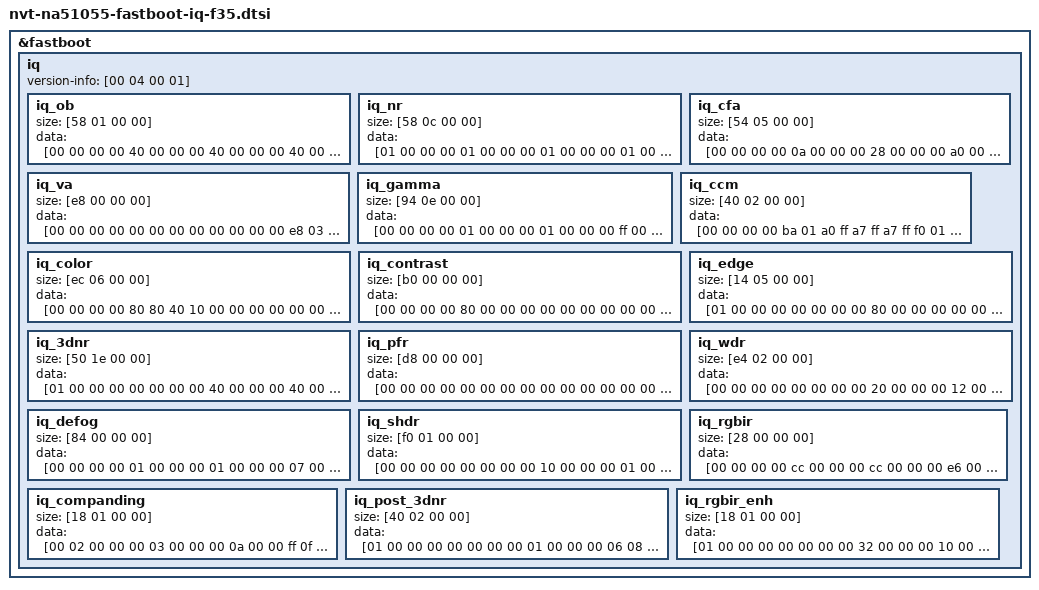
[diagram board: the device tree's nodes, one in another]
/*
 * Novatek Ltd. NA51055 BSP part of dts
 *
 * Cortex-A9
 *
 */

&fastboot {
	     iq {
		version-info = [00 04 00 01];
		iq_ob {
			size = [58 01 00 00];
			data = [00 00 00 00 40 00 00 00 40 00 00 00 40 00 00 00 40 00 00 00 40 00 00 00 40 00 00 00 40 00 00 00 40 00 00 00 40 00 00 00 40 00 00 00 40 00 00 00 40 00 00 00 40 00 00 00 40 00 00 00 40 00 00 00 40 00 00 00 40 00 00 00 40 00 00 00 40 00 00 00 40 00 00 00 40 00 00 00 40 00 00 00 40 00 00 00 40 00 00 00 40 00 00 00 40 00 00 00 40 00 00 00 40 00 00 00 40 00 00 00 40 00 00 00 40 00 00 00 40 00 00 00 40 00 00 00 40 00 00 00 40 00 00 00 40 00 00 00 40 00 00 00 40 00 00 00 40 00 00 00 40 00 00 00 40 00 00 00 40 00 00 00 40 00 00 00 40 00 00 00 40 00 00 00 40 00 00 00 40 00 00 00 40 00 00 00 40 00 00 00 40 00 00 00 40 00 00 00 40 00 00 00 40 00 00 00 40 00 00 00 40 00 00 00 40 00 00 00 40 00 00 00 40 00 00 00 40 00 00 00 40 00 00 00 40 00 00 00 40 00 00 00 40 00 00 00 40 00 00 00 40 00 00 00 40 00 00 00 40 00 00 00 40 00 00 00 40 00 00 00 40 00 00 00 40 00 00 00 40 00 00 00 40 00 00 00 40 00 00 00 40 00 00 00 40 00 00 00 40 00 00 00 40 00 00 00 40 00 00 00 40 00 00 00 40 00 00 00 40 00 00 00 40 00 00 00 40 00 00 00 40 00 00 00];
		};
		iq_nr {
			size = [58 0c 00 00];
			data = [01 00 00 00 01 00 00 00 01 00 00 00 01 00 00 00 01 00 00 00 00 00 00 00 00 00 00 00 00 01 00 00 00 00 00 00 ff 0f 00 00 ff 0f 00 00 ff 0f 00 00 ff 0f 00 00 ff 0f 00 00 ff 0f 00 00 ff 0f 00 00 ff 0f 00 00 ff 0f 00 00 ff 0f 00 00 00 01 80 00 00 00 00 00 00 00 00 00 00 00 00 00 00 00 00 00 00 00 00 00 00 00 00 00 00 00 00 00 00 00 00 00 00 00 00 00 00 00 00 00 00 00 00 00 00 00 00 00 00 00 00 00 00 00 00 00 00 00 00 00 00 00 00 00 00 00 00 00 00 00 00 00 00 00 00 00 00 00 00 00 00 00 00 00 00 00 00 00 00 00 00 00 00 00 00 00 00 00 00 00 80 00 00 00 00 00 00 00 00 00 00 00 00 00 00 00 00 00 00 00 00 00 00 00 00 00 00 00 02 00 00 00 02 00 00 00 00 00 00 00 c6 02 00 00 0c 04 00 00 af 06 00 00 3d 09 00 00 41 0f 00 00 c6 02 00 00 0c 04 00 00 af 06 00 00 3d 09 00 00 41 0f 00 00 00 00 80 00 00 00 00 00 02 00 00 00 03 00 00 00 04 00 00 00 04 00 00 00 06 00 00 00 00 00 00 00 03 00 00 00 05 00 00 00 06 00 00 00 06 00 00 00 06 00 00 00 06 00 00 00 06 00 00 00 06 00 00 00 06 00 00 00 06 00 00 00 06 00 00 00 06 00 00 00 06 00 00 00 06 00 00 00 06 00 00 00 06 00 00 00 00 00 00 00 40 00 00 00 30 00 00 00 08 00 00 00 08 00 00 00 08 00 00 00 08 00 00 00 00 00 00 00 06 00 00 00 00 00 00 00 00 00 00 00 00 00 00 00 c6 02 00 00 0c 04 00 00 af 06 00 00 3d 09 00 00 41 0f 00 00 c6 02 00 00 0c 04 00 00 af 06 00 00 3d 09 00 00 41 0f 00 00 00 00 80 00 00 00 00 00 02 00 00 00 03 00 00 00 04 00 00 00 04 00 00 00 06 00 00 00 00 00 00 00 03 00 00 00 05 00 00 00 06 00 00 00 08 00 00 00 08 00 00 00 08 00 00 00 08 00 00 00 08 00 00 00 08 00 00 00 08 00 00 00 08 00 00 00 08 00 00 00 08 00 00 00 08 00 00 00 08 00 00 00 08 00 00 00 00 00 00 00 20 00 00 00 10 00 00 00 08 00 00 00 08 00 00 00 08 00 00 00 08 00 00 00 00 00 00 00 08 00 00 00 00 00 00 00 00 00 00 00 00 00 00 00 c6 02 00 00 0c 04 00 00 af 06 00 00 3d 09 00 00 41 0f 00 00 c6 02 00 00 0c 04 00 00 af 06 00 00 3d 09 00 00 41 0f 00 00 00 00 80 00 00 00 00 00 02 00 00 00 03 00 00 00 04 00 00 00 04 00 00 00 06 00 00 00 00 00 00 00 06 00 00 00 0a 00 00 00 0c 00 00 00 0e 00 00 00 0c 00 00 00 0a 00 00 00 0a 00 00 00 0a 00 00 00 0a 00 00 00 0a 00 00 00 0a 00 00 00 0a 00 00 00 0a 00 00 00 0a 00 00 00 0a 00 00 00 0a 00 00 00 02 00 00 00 20 00 00 00 00 00 00 00 08 00 00 00 0a 00 00 00 08 00 00 00 0a 00 00 00 00 00 00 00 0c 00 00 00 00 00 00 00 00 00 00 00 00 00 00 00 20 00 00 00 68 04 00 00 45 07 00 00 fe 0b 00 00 ff 0f 00 00 c6 02 00 00 0c 04 00 00 af 06 00 00 3d 09 00 00 41 0f 00 00 00 00 80 00 00 00 00 00 02 00 00 00 03 00 00 00 04 00 00 00 04 00 00 00 06 00 00 00 00 00 00 00 0a 00 00 00 0a 00 00 00 0c 00 00 00 0e 00 00 00 10 00 00 00 11 00 00 00 13 00 00 00 14 00 00 00 14 00 00 00 14 00 00 00 14 00 00 00 14 00 00 00 14 00 00 00 14 00 00 00 14 00 00 00 14 00 00 00 04 00 00 00 00 00 00 00 00 00 00 00 08 00 00 00 0a 00 00 00 08 00 00 00 0a 00 00 00 03 00 00 00 0c 00 00 00 00 00 00 00 01 00 00 00 00 00 00 00 20 00 00 00 56 05 00 00 ce 08 00 00 c4 0c 00 00 ff 0f 00 00 20 00 00 00 cd 05 00 00 92 09 00 00 e1 0d 00 00 ff 0f 00 00 00 00 80 00 00 00 00 00 04 00 00 00 07 00 00 00 08 00 00 00 09 00 00 00 0e 00 00 00 00 00 00 00 0c 00 00 00 12 00 00 00 16 00 00 00 19 00 00 00 1c 00 00 00 1f 00 00 00 21 00 00 00 24 00 00 00 26 00 00 00 28 00 00 00 2a 00 00 00 2c 00 00 00 2e 00 00 00 2f 00 00 00 31 00 00 00 33 00 00 00 04 00 00 00 06 00 00 00 60 00 00 00 08 00 00 00 0a 00 00 00 08 00 00 00 0a 00 00 00 09 00 00 00 10 00 00 00 00 00 00 00 01 00 00 00 00 00 00 00 20 00 00 00 56 05 00 00 ce 08 00 00 c4 0c 00 00 ff 0f 00 00 20 00 00 00 cd 05 00 00 92 09 00 00 e1 0d 00 00 ff 0f 00 00 00 00 80 00 00 00 00 00 04 00 00 00 07 00 00 00 08 00 00 00 09 00 00 00 0e 00 00 00 00 00 00 00 0d 00 00 00 12 00 00 00 16 00 00 00 1a 00 00 00 1d 00 00 00 20 00 00 00 22 00 00 00 25 00 00 00 27 00 00 00 29 00 00 00 2b 00 00 00 2d 00 00 00 2f 00 00 00 31 00 00 00 33 00 00 00 34 00 00 00 04 00 00 00 04 00 00 00 40 00 00 00 08 00 00 00 0a 00 00 00 08 00 00 00 0a 00 00 00 09 00 00 00 10 00 00 00 00 00 00 00 01 00 00 00 00 00 00 00 20 00 00 00 68 04 00 00 45 07 00 00 fe 0b 00 00 ff 0f 00 00 c6 02 00 00 0c 04 00 00 af 06 00 00 3d 09 00 00 41 0f 00 00 00 00 80 00 00 00 00 00 06 00 00 00 09 00 00 00 0b 00 00 00 0c 00 00 00 12 00 00 00 00 00 00 00 08 00 00 00 0c 00 00 00 0f 00 00 00 11 00 00 00 13 00 00 00 15 00 00 00 17 00 00 00 18 00 00 00 1a 00 00 00 1b 00 00 00 1d 00 00 00 1e 00 00 00 1f 00 00 00 20 00 00 00 22 00 00 00 23 00 00 00 06 00 00 00 04 00 00 00 40 00 00 00 08 00 00 00 0a 00 00 00 08 00 00 00 08 00 00 00 0e 00 00 00 0f 00 00 00 00 00 00 00 01 00 00 00 00 00 00 00 c6 02 00 00 0c 04 00 00 af 06 00 00 3d 09 00 00 41 0f 00 00 c6 02 00 00 0c 04 00 00 af 06 00 00 3d 09 00 00 41 0f 00 00 09 00 80 00 00 00 00 00 08 00 00 00 0b 00 00 00 0e 00 00 00 10 00 00 00 17 00 00 00 00 00 00 00 0f 00 00 00 12 00 00 00 1d 00 00 00 21 00 00 00 25 00 00 00 29 00 00 00 2c 00 00 00 2f 00 00 00 32 00 00 00 35 00 00 00 37 00 00 00 3a 00 00 00 3c 00 00 00 3e 00 00 00 41 00 00 00 43 00 00 00 0c 00 00 00 00 00 00 00 00 00 00 00 0a 00 00 00 10 00 00 00 0a 00 00 00 10 00 00 00 06 00 00 00 13 00 00 00 01 00 00 00 02 00 00 00 00 00 00 00 c6 02 00 00 0c 04 00 00 af 06 00 00 3d 09 00 00 41 0f 00 00 c6 02 00 00 0c 04 00 00 af 06 00 00 3d 09 00 00 41 0f 00 00 09 00 80 00 00 00 00 00 0d 00 00 00 12 00 00 00 16 00 00 00 1a 00 00 00 25 00 00 00 00 00 00 00 18 00 00 00 21 00 00 00 29 00 00 00 30 00 00 00 35 00 00 00 3a 00 00 00 3f 00 00 00 43 00 00 00 48 00 00 00 4b 00 00 00 4f 00 00 00 53 00 00 00 56 00 00 00 59 00 00 00 5c 00 00 00 60 00 00 00 00 00 00 00 20 00 00 00 20 00 00 00 10 00 00 00 10 00 00 00 10 00 00 00 10 00 00 00 0a 00 00 00 12 00 00 00 02 00 00 00 03 00 00 00 00 00 00 00 c6 02 00 00 0c 04 00 00 af 06 00 00 3d 09 00 00 41 0f 00 00 c6 02 00 00 0c 04 00 00 af 06 00 00 3d 09 00 00 41 0f 00 00 09 00 80 00 00 00 00 00 16 00 00 00 1f 00 00 00 26 00 00 00 2c 00 00 00 3e 00 00 00 00 00 00 00 1e 00 00 00 2a 00 00 00 34 00 00 00 3c 00 00 00 43 00 00 00 4a 00 00 00 50 00 00 00 55 00 00 00 5b 00 00 00 60 00 00 00 64 00 00 00 69 00 00 00 6d 00 00 00 71 00 00 00 75 00 00 00 79 00 00 00 00 00 00 00 20 00 00 00 40 00 00 00 10 00 00 00 10 00 00 00 10 00 00 00 10 00 00 00 0a 00 00 00 12 00 00 00 02 00 00 00 03 00 00 00 00 00 00 00 c6 02 00 00 0c 04 00 00 af 06 00 00 3d 09 00 00 41 0f 00 00 c6 02 00 00 0c 04 00 00 af 06 00 00 3d 09 00 00 41 0f 00 00 09 00 80 00 00 00 00 00 10 00 00 00 16 00 00 00 1c 00 00 00 20 00 00 00 2d 00 00 00 00 00 00 00 17 00 00 00 20 00 00 00 28 00 00 00 2e 00 00 00 33 00 00 00 38 00 00 00 3d 00 00 00 41 00 00 00 45 00 00 00 49 00 00 00 4c 00 00 00 50 00 00 00 53 00 00 00 56 00 00 00 59 00 00 00 5c 00 00 00 00 00 00 00 20 00 00 00 40 00 00 00 10 00 00 00 10 00 00 00 10 00 00 00 10 00 00 00 18 00 00 00 14 00 00 00 01 00 00 00 01 00 00 00 00 00 00 00 c6 02 00 00 0c 04 00 00 af 06 00 00 3d 09 00 00 41 0f 00 00 c6 02 00 00 0c 04 00 00 af 06 00 00 3d 09 00 00 41 0f 00 00 09 00 80 00 00 00 00 00 21 00 00 00 2f 00 00 00 3a 00 00 00 43 00 00 00 5f 00 00 00 00 00 00 00 27 00 00 00 38 00 00 00 44 00 00 00 4f 00 00 00 58 00 00 00 60 00 00 00 68 00 00 00 70 00 00 00 76 00 00 00 7d 00 00 00 83 00 00 00 89 00 00 00 8e 00 00 00 94 00 00 00 99 00 00 00 9e 00 00 00 00 00 00 00 20 00 00 00 20 00 00 00 10 00 00 00 10 00 00 00 10 00 00 00 10 00 00 00 1a 00 00 00 14 00 00 00 01 00 00 00 01 00 00 00 00 00 00 00 c6 02 00 00 0c 04 00 00 af 06 00 00 3d 09 00 00 41 0f 00 00 c6 02 00 00 0c 04 00 00 af 06 00 00 3d 09 00 00 41 0f 00 00 09 00 80 00 00 00 00 00 2e 00 00 00 42 00 00 00 51 00 00 00 5d 00 00 00 84 00 00 00 00 00 00 00 32 00 00 00 47 00 00 00 57 00 00 00 65 00 00 00 71 00 00 00 7c 00 00 00 86 00 00 00 8f 00 00 00 98 00 00 00 a0 00 00 00 a8 00 00 00 af 00 00 00 b7 00 00 00 be 00 00 00 c4 00 00 00 cb 00 00 00 00 00 00 00 20 00 00 00 20 00 00 00 10 00 00 00 10 00 00 00 10 00 00 00 10 00 00 00 1c 00 00 00 16 00 00 00 01 00 00 00 01 00 00 00 00 00 00 00 c6 02 00 00 0c 04 00 00 af 06 00 00 3d 09 00 00 41 0f 00 00 c6 02 00 00 0c 04 00 00 af 06 00 00 3d 09 00 00 41 0f 00 00 09 00 80 00 00 00 00 00 2e 00 00 00 42 00 00 00 51 00 00 00 5d 00 00 00 84 00 00 00 00 00 00 00 32 00 00 00 47 00 00 00 57 00 00 00 65 00 00 00 71 00 00 00 7c 00 00 00 86 00 00 00 8f 00 00 00 98 00 00 00 a0 00 00 00 a8 00 00 00 af 00 00 00 b7 00 00 00 be 00 00 00 c4 00 00 00 cb 00 00 00 00 00 00 00 20 00 00 00 20 00 00 00 10 00 00 00 10 00 00 00 10 00 00 00 10 00 00 00 1c 00 00 00 16 00 00 00 01 00 00 00 01 00 00 00 00 00 00 00 c6 02 00 00 0c 04 00 00 af 06 00 00 3d 09 00 00 41 0f 00 00 c6 02 00 00 0c 04 00 00 af 06 00 00 3d 09 00 00 41 0f 00 00 09 00 80 00 00 00 00 00 2e 00 00 00 42 00 00 00 51 00 00 00 5d 00 00 00 84 00 00 00 00 00 00 00 32 00 00 00 47 00 00 00 57 00 00 00 65 00 00 00 71 00 00 00 7c 00 00 00 86 00 00 00 8f 00 00 00 98 00 00 00 a0 00 00 00 a8 00 00 00 af 00 00 00 b7 00 00 00 be 00 00 00 c4 00 00 00 cb 00 00 00 00 00 00 00 20 00 00 00 20 00 00 00 10 00 00 00 10 00 00 00 10 00 00 00 10 00 00 00 1c 00 00 00 16 00 00 00 01 00 00 00 01 00 00 00 00 00 00 00 c6 02 00 00 0c 04 00 00 af 06 00 00 3d 09 00 00 41 0f 00 00 c6 02 00 00 0c 04 00 00 af 06 00 00 3d 09 00 00 41 0f 00 00 09 00 80 00 00 00 00 00 2e 00 00 00 42 00 00 00 51 00 00 00 5d 00 00 00 84 00 00 00 00 00 00 00 32 00 00 00 47 00 00 00 57 00 00 00 65 00 00 00 71 00 00 00 7c 00 00 00 86 00 00 00 8f 00 00 00 98 00 00 00 a0 00 00 00 a8 00 00 00 af 00 00 00 b7 00 00 00 be 00 00 00 c4 00 00 00 cb 00 00 00 00 00 00 00 20 00 00 00 20 00 00 00 10 00 00 00 10 00 00 00 10 00 00 00 10 00 00 00 1c 00 00 00 16 00 00 00 01 00 00 00 01 00 00 00];
		};
		iq_cfa {
			size = [54 05 00 00];
			data = [00 00 00 00 0a 00 00 00 28 00 00 00 a0 00 00 00 40 00 00 00 0f 00 00 00 0f 00 00 00 07 00 00 00 04 00 00 00 03 00 00 00 02 00 00 00 02 00 00 00 01 00 00 00 01 00 00 00 01 00 00 00 01 00 00 00 00 00 00 00 00 00 00 00 00 00 00 00 00 00 00 00 00 00 00 00 28 00 00 00 a0 00 00 00 a0 00 00 00 40 00 00 00 0f 00 00 00 0f 00 00 00 07 00 00 00 04 00 00 00 03 00 00 00 02 00 00 00 02 00 00 00 01 00 00 00 01 00 00 00 01 00 00 00 01 00 00 00 00 00 00 00 00 00 00 00 00 00 00 00 00 00 00 00 00 00 00 00 28 00 00 00 28 00 00 00 a0 00 00 00 40 00 00 00 0f 00 00 00 0f 00 00 00 07 00 00 00 04 00 00 00 03 00 00 00 02 00 00 00 02 00 00 00 01 00 00 00 01 00 00 00 01 00 00 00 01 00 00 00 00 00 00 00 00 00 00 00 00 00 00 00 00 00 00 00 00 00 00 00 0a 00 00 00 28 00 00 00 a0 00 00 00 40 00 00 00 0f 00 00 00 0f 00 00 00 07 00 00 00 04 00 00 00 03 00 00 00 02 00 00 00 02 00 00 00 01 00 00 00 01 00 00 00 01 00 00 00 01 00 00 00 00 00 00 00 00 00 00 00 00 00 00 00 00 00 00 00 00 00 00 00 28 00 00 00 28 00 00 00 a0 00 00 00 40 00 00 00 0f 00 00 00 0f 00 00 00 07 00 00 00 04 00 00 00 03 00 00 00 02 00 00 00 02 00 00 00 01 00 00 00 01 00 00 00 01 00 00 00 01 00 00 00 00 00 00 00 00 00 00 00 00 00 00 00 00 00 00 00 00 00 00 00 28 00 00 00 28 00 00 00 a0 00 00 00 40 00 00 00 0f 00 00 00 0f 00 00 00 07 00 00 00 04 00 00 00 03 00 00 00 02 00 00 00 02 00 00 00 01 00 00 00 01 00 00 00 01 00 00 00 01 00 00 00 00 00 00 00 00 00 00 00 00 00 00 00 00 00 00 00 00 00 00 00 0a 00 00 00 28 00 00 00 a0 00 00 00 40 00 00 00 0f 00 00 00 0f 00 00 00 07 00 00 00 04 00 00 00 03 00 00 00 02 00 00 00 02 00 00 00 01 00 00 00 01 00 00 00 01 00 00 00 01 00 00 00 00 00 00 00 00 00 00 00 00 00 00 00 00 00 00 00 00 00 00 00 0a 00 00 00 28 00 00 00 a0 00 00 00 40 00 00 00 0f 00 00 00 0f 00 00 00 07 00 00 00 04 00 00 00 03 00 00 00 02 00 00 00 02 00 00 00 01 00 00 00 01 00 00 00 01 00 00 00 01 00 00 00 00 00 00 00 00 00 00 00 00 00 00 00 00 00 00 00 00 00 00 00 0a 00 00 00 28 00 00 00 a0 00 00 00 40 00 00 00 0f 00 00 00 0f 00 00 00 07 00 00 00 04 00 00 00 03 00 00 00 02 00 00 00 02 00 00 00 01 00 00 00 01 00 00 00 01 00 00 00 01 00 00 00 00 00 00 00 00 00 00 00 00 00 00 00 00 00 00 00 00 00 00 00 0a 00 00 00 28 00 00 00 a0 00 00 00 40 00 00 00 0f 00 00 00 0f 00 00 00 07 00 00 00 04 00 00 00 03 00 00 00 02 00 00 00 02 00 00 00 01 00 00 00 01 00 00 00 01 00 00 00 01 00 00 00 00 00 00 00 00 00 00 00 00 00 00 00 00 00 00 00 00 00 00 00 0a 00 00 00 28 00 00 00 a0 00 00 00 40 00 00 00 0f 00 00 00 0f 00 00 00 07 00 00 00 04 00 00 00 03 00 00 00 02 00 00 00 02 00 00 00 01 00 00 00 01 00 00 00 01 00 00 00 01 00 00 00 00 00 00 00 00 00 00 00 00 00 00 00 00 00 00 00 00 00 00 00 0a 00 00 00 28 00 00 00 a0 00 00 00 20 00 00 00 08 00 00 00 08 00 00 00 03 00 00 00 02 00 00 00 01 00 00 00 01 00 00 00 01 00 00 00 00 00 00 00 00 00 00 00 00 00 00 00 00 00 00 00 00 00 00 00 00 00 00 00 00 00 00 00 00 00 00 00 00 00 00 00 0a 00 00 00 28 00 00 00 a0 00 00 00 20 00 00 00 08 00 00 00 08 00 00 00 03 00 00 00 02 00 00 00 01 00 00 00 01 00 00 00 01 00 00 00 00 00 00 00 00 00 00 00 00 00 00 00 00 00 00 00 00 00 00 00 00 00 00 00 00 00 00 00 00 00 00 00 00 00 00 00 0a 00 00 00 28 00 00 00 a0 00 00 00 40 00 00 00 0f 00 00 00 0f 00 00 00 07 00 00 00 04 00 00 00 03 00 00 00 02 00 00 00 02 00 00 00 01 00 00 00 01 00 00 00 01 00 00 00 01 00 00 00 00 00 00 00 00 00 00 00 00 00 00 00 00 00 00 00 00 00 00 00 0a 00 00 00 28 00 00 00 a0 00 00 00 40 00 00 00 0f 00 00 00 0f 00 00 00 07 00 00 00 04 00 00 00 03 00 00 00 02 00 00 00 02 00 00 00 01 00 00 00 01 00 00 00 01 00 00 00 01 00 00 00 00 00 00 00 00 00 00 00 00 00 00 00 00 00 00 00 00 00 00 00 0a 00 00 00 28 00 00 00 a0 00 00 00 40 00 00 00 0f 00 00 00 0f 00 00 00 07 00 00 00 04 00 00 00 03 00 00 00 02 00 00 00 02 00 00 00 01 00 00 00 01 00 00 00 01 00 00 00 01 00 00 00 00 00 00 00 00 00 00 00 00 00 00 00 00 00 00 00 00 00 00 00 0a 00 00 00 28 00 00 00 a0 00 00 00 40 00 00 00 0f 00 00 00 0f 00 00 00 07 00 00 00 04 00 00 00 03 00 00 00 02 00 00 00 02 00 00 00 01 00 00 00 01 00 00 00 01 00 00 00 01 00 00 00 00 00 00 00 00 00 00 00 00 00 00 00 00 00 00 00 00 00 00 00];
		};
		iq_va {
			size = [e8 00 00 00];
			data = [00 00 00 00 00 00 00 00 00 00 00 00 e8 03 00 00 e8 03 00 00 00 00 00 00 00 00 00 00 e8 03 00 00 e8 03 00 00 00 00 00 00 00 00 00 00 e8 03 00 00 e8 03 00 00 00 00 00 00 00 00 00 00 e8 03 00 00 e8 03 00 00 00 00 00 00 00 00 00 00 e8 03 00 00 e8 03 00 00 02 ff 00 00 03 02 ff 00 00 03 06 00 08 00 06 00 08 00 06 00 08 00 06 00 08 00 06 00 08 00 06 00 08 00 06 00 08 00 06 00 08 00 06 00 08 00 06 00 08 00 06 00 08 00 06 00 08 00 06 00 08 00 06 00 08 00 06 00 08 00 06 00 08 00 06 00 08 00 06 00 08 00 06 00 08 00 06 00 08 00 06 00 08 00 06 00 08 00 06 00 08 00 06 00 08 00 06 00 08 00 06 00 08 00 06 00 08 00 06 00 08 00 06 00 08 00 06 00 08 00 06 00 08 00 06 00 08 00 06 00 08 00 06 00 08 00 00 00];
		};
		iq_gamma {
			size = [94 0e 00 00];
			data = [00 00 00 00 01 00 00 00 01 00 00 00 ff 00 00 00 ff 00 00 00 ff 00 00 00 ff 00 00 00 ff 00 00 00 ff 00 00 00 ff 00 00 00 ff 00 00 00 ff 00 00 00 ff 00 00 00 ff 00 00 00 ff 00 00 00 ff 00 00 00 ff 00 00 00 ff 00 00 00 ff 00 00 00 ff 00 00 00 00 00 00 00 08 00 00 00 10 00 00 00 18 00 00 00 1c 00 00 00 20 00 00 00 24 00 00 00 26 00 00 00 28 00 00 00 29 00 00 00 2a 00 00 00 2b 00 00 00 2c 00 00 00 2d 00 00 00 2e 00 00 00 2f 00 00 00 30 00 00 00 31 00 00 00 32 00 00 00 33 00 00 00 34 00 00 00 35 00 00 00 36 00 00 00 37 00 00 00 38 00 00 00 39 00 00 00 3a 00 00 00 3b 00 00 00 3c 00 00 00 3d 00 00 00 3e 00 00 00 3f 00 00 00 03 00 00 00 03 00 00 00 03 00 00 00 02 00 00 00 02 00 00 00 02 00 00 00 01 00 00 00 01 00 00 00 00 00 00 00 00 00 00 00 00 00 00 00 00 00 00 00 00 00 00 00 00 00 00 00 00 00 00 00 00 00 00 00 00 00 00 00 00 00 00 00 00 00 00 00 00 00 00 00 00 00 00 00 00 00 00 00 00 00 00 00 00 00 00 00 00 00 00 00 00 00 00 00 00 00 00 00 00 00 00 00 00 00 00 00 00 00 00 00 00 00 00 00 00 00 00 00 00 00 00 00 05 00 00 00 18 00 00 00 3f 00 00 00 64 00 00 00 82 00 00 00 a3 00 00 00 cb 00 00 00 ed 00 00 00 fd 00 00 00 0e 01 00 00 1d 01 00 00 2d 01 00 00 3b 01 00 00 49 01 00 00 57 01 00 00 65 01 00 00 71 01 00 00 7e 01 00 00 8a 01 00 00 96 01 00 00 a1 01 00 00 ac 01 00 00 b6 01 00 00 c1 01 00 00 d9 01 00 00 f2 01 00 00 0c 02 00 00 27 02 00 00 40 02 00 00 5a 02 00 00 73 02 00 00 8d 02 00 00 ad 02 00 00 cd 02 00 00 ed 02 00 00 0e 03 00 00 4e 03 00 00 8f 03 00 00 d0 03 00 00 11 04 00 00 92 04 00 00 14 05 00 00 95 05 00 00 17 06 00 00 94 06 00 00 0f 07 00 00 89 07 00 00 02 08 00 00 80 08 00 00 ff 08 00 00 80 09 00 00 02 0a 00 00 85 0a 00 00 09 0b 00 00 8f 0b 00 00 17 0c 00 00 99 0c 00 00 1b 0d 00 00 9d 0d 00 00 20 0e 00 00 9b 0e 00 00 15 0f 00 00 8b 0f 00 00 ff 0f 00 00 00 00 00 00 08 00 00 00 10 00 00 00 18 00 00 00 1c 00 00 00 20 00 00 00 24 00 00 00 26 00 00 00 28 00 00 00 29 00 00 00 2a 00 00 00 2b 00 00 00 2c 00 00 00 2d 00 00 00 2e 00 00 00 2f 00 00 00 30 00 00 00 31 00 00 00 32 00 00 00 33 00 00 00 34 00 00 00 35 00 00 00 36 00 00 00 37 00 00 00 38 00 00 00 39 00 00 00 3a 00 00 00 3b 00 00 00 3c 00 00 00 3d 00 00 00 3e 00 00 00 3f 00 00 00 03 00 00 00 03 00 00 00 03 00 00 00 02 00 00 00 02 00 00 00 02 00 00 00 01 00 00 00 01 00 00 00 00 00 00 00 00 00 00 00 00 00 00 00 00 00 00 00 00 00 00 00 00 00 00 00 00 00 00 00 00 00 00 00 00 00 00 00 00 00 00 00 00 00 00 00 00 00 00 00 00 00 00 00 00 00 00 00 00 00 00 00 00 00 00 00 00 00 00 00 00 00 00 00 00 00 00 00 00 00 00 00 00 00 00 00 00 00 00 00 00 00 00 00 00 00 00 00 05 00 00 00 00 00 00 00 00 00 00 00 10 00 00 00 20 00 00 00 30 00 00 00 40 00 00 00 50 00 00 00 60 00 00 00 70 00 00 00 80 00 00 00 90 00 00 00 a0 00 00 00 b0 00 00 00 c0 00 00 00 d0 00 00 00 e0 00 00 00 f0 00 00 00 00 01 00 00 10 01 00 00 20 01 00 00 30 01 00 00 40 01 00 00 50 01 00 00 60 01 00 00 70 01 00 00 80 01 00 00 a0 01 00 00 c0 01 00 00 e0 01 00 00 00 02 00 00 20 02 00 00 40 02 00 00 60 02 00 00 80 02 00 00 a0 02 00 00 c0 02 00 00 e0 02 00 00 00 03 00 00 40 03 00 00 80 03 00 00 c0 03 00 00 00 04 00 00 80 04 00 00 00 05 00 00 80 05 00 00 00 06 00 00 80 06 00 00 00 07 00 00 80 07 00 00 00 08 00 00 80 08 00 00 00 09 00 00 80 09 00 00 00 0a 00 00 80 0a 00 00 00 0b 00 00 80 0b 00 00 00 0c 00 00 80 0c 00 00 00 0d 00 00 80 0d 00 00 00 0e 00 00 80 0e 00 00 00 0f 00 00 80 0f 00 00 ff 0f 00 00 19 00 00 00 00 00 00 00 10 00 00 00 20 00 00 00 30 00 00 00 40 00 00 00 50 00 00 00 60 00 00 00 70 00 00 00 80 00 00 00 90 00 00 00 a0 00 00 00 b0 00 00 00 c0 00 00 00 d0 00 00 00 e0 00 00 00 f0 00 00 00 00 01 00 00 10 01 00 00 20 01 00 00 30 01 00 00 40 01 00 00 50 01 00 00 60 01 00 00 70 01 00 00 80 01 00 00 a0 01 00 00 c0 01 00 00 e0 01 00 00 00 02 00 00 20 02 00 00 40 02 00 00 60 02 00 00 80 02 00 00 a0 02 00 00 c0 02 00 00 e0 02 00 00 00 03 00 00 40 03 00 00 80 03 00 00 c0 03 00 00 00 04 00 00 80 04 00 00 00 05 00 00 80 05 00 00 00 06 00 00 80 06 00 00 00 07 00 00 80 07 00 00 00 08 00 00 80 08 00 00 00 09 00 00 80 09 00 00 00 0a 00 00 80 0a 00 00 00 0b 00 00 80 0b 00 00 00 0c 00 00 80 0c 00 00 00 0d 00 00 80 0d 00 00 00 0e 00 00 80 0e 00 00 00 0f 00 00 80 0f 00 00 ff 0f 00 00 32 00 00 00 00 00 00 00 10 00 00 00 20 00 00 00 30 00 00 00 40 00 00 00 50 00 00 00 60 00 00 00 70 00 00 00 80 00 00 00 90 00 00 00 a0 00 00 00 b0 00 00 00 c0 00 00 00 d0 00 00 00 e0 00 00 00 f0 00 00 00 00 01 00 00 10 01 00 00 20 01 00 00 30 01 00 00 40 01 00 00 50 01 00 00 60 01 00 00 70 01 00 00 80 01 00 00 a0 01 00 00 c0 01 00 00 e0 01 00 00 00 02 00 00 20 02 00 00 40 02 00 00 60 02 00 00 80 02 00 00 a0 02 00 00 c0 02 00 00 e0 02 00 00 00 03 00 00 40 03 00 00 80 03 00 00 c0 03 00 00 00 04 00 00 80 04 00 00 00 05 00 00 80 05 00 00 00 06 00 00 80 06 00 00 00 07 00 00 80 07 00 00 00 08 00 00 80 08 00 00 00 09 00 00 80 09 00 00 00 0a 00 00 80 0a 00 00 00 0b 00 00 80 0b 00 00 00 0c 00 00 80 0c 00 00 00 0d 00 00 80 0d 00 00 00 0e 00 00 80 0e 00 00 00 0f 00 00 80 0f 00 00 ff 0f 00 00 4b 00 00 00 00 00 00 00 10 00 00 00 20 00 00 00 30 00 00 00 40 00 00 00 50 00 00 00 60 00 00 00 70 00 00 00 80 00 00 00 90 00 00 00 a0 00 00 00 b0 00 00 00 c0 00 00 00 d0 00 00 00 e0 00 00 00 f0 00 00 00 00 01 00 00 10 01 00 00 20 01 00 00 30 01 00 00 40 01 00 00 50 01 00 00 60 01 00 00 70 01 00 00 80 01 00 00 a0 01 00 00 c0 01 00 00 e0 01 00 00 00 02 00 00 20 02 00 00 40 02 00 00 60 02 00 00 80 02 00 00 a0 02 00 00 c0 02 00 00 e0 02 00 00 00 03 00 00 40 03 00 00 80 03 00 00 c0 03 00 00 00 04 00 00 80 04 00 00 00 05 00 00 80 05 00 00 00 06 00 00 80 06 00 00 00 07 00 00 80 07 00 00 00 08 00 00 80 08 00 00 00 09 00 00 80 09 00 00 00 0a 00 00 80 0a 00 00 00 0b 00 00 80 0b 00 00 00 0c 00 00 80 0c 00 00 00 0d 00 00 80 0d 00 00 00 0e 00 00 80 0e 00 00 00 0f 00 00 80 0f 00 00 ff 0f 00 00 64 00 00 00 00 00 00 00 10 00 00 00 20 00 00 00 30 00 00 00 40 00 00 00 50 00 00 00 60 00 00 00 70 00 00 00 80 00 00 00 90 00 00 00 a0 00 00 00 b0 00 00 00 c0 00 00 00 d0 00 00 00 e0 00 00 00 f0 00 00 00 00 01 00 00 10 01 00 00 20 01 00 00 30 01 00 00 40 01 00 00 50 01 00 00 60 01 00 00 70 01 00 00 80 01 00 00 a0 01 00 00 c0 01 00 00 e0 01 00 00 00 02 00 00 20 02 00 00 40 02 00 00 60 02 00 00 80 02 00 00 a0 02 00 00 c0 02 00 00 e0 02 00 00 00 03 00 00 40 03 00 00 80 03 00 00 c0 03 00 00 00 04 00 00 80 04 00 00 00 05 00 00 80 05 00 00 00 06 00 00 80 06 00 00 00 07 00 00 80 07 00 00 00 08 00 00 80 08 00 00 00 09 00 00 80 09 00 00 00 0a 00 00 80 0a 00 00 00 0b 00 00 80 0b 00 00 00 0c 00 00 80 0c 00 00 00 0d 00 00 80 0d 00 00 00 0e 00 00 80 0e 00 00 00 0f 00 00 80 0f 00 00 ff 0f 00 00 00 00 00 00 32 00 00 00 5a 00 00 00 78 00 00 00 97 00 00 00 b4 00 00 00 cc 00 00 00 e5 00 00 00 fc 00 00 00 14 01 00 00 2c 01 00 00 42 01 00 00 56 01 00 00 67 01 00 00 76 01 00 00 83 01 00 00 8e 01 00 00 9a 01 00 00 a6 01 00 00 b1 01 00 00 bc 01 00 00 c6 01 00 00 cf 01 00 00 d8 01 00 00 e1 01 00 00 ea 01 00 00 f2 01 00 00 fb 01 00 00 03 02 00 00 0b 02 00 00 12 02 00 00 1a 02 00 00 21 02 00 00 28 02 00 00 2f 02 00 00 36 02 00 00 3d 02 00 00 43 02 00 00 4a 02 00 00 50 02 00 00 57 02 00 00 5d 02 00 00 63 02 00 00 69 02 00 00 6e 02 00 00 74 02 00 00 79 02 00 00 7f 02 00 00 84 02 00 00 8a 02 00 00 90 02 00 00 96 02 00 00 9b 02 00 00 a1 02 00 00 a7 02 00 00 ac 02 00 00 b2 02 00 00 b7 02 00 00 bd 02 00 00 c2 02 00 00 c8 02 00 00 cd 02 00 00 d2 02 00 00 d7 02 00 00 dd 02 00 00 e2 02 00 00 e7 02 00 00 ec 02 00 00 f2 02 00 00 f7 02 00 00 fc 02 00 00 01 03 00 00 06 03 00 00 0b 03 00 00 11 03 00 00 16 03 00 00 1b 03 00 00 20 03 00 00 25 03 00 00 2a 03 00 00 2f 03 00 00 34 03 00 00 38 03 00 00 3d 03 00 00 42 03 00 00 47 03 00 00 4c 03 00 00 51 03 00 00 55 03 00 00 5a 03 00 00 5f 03 00 00 63 03 00 00 68 03 00 00 6d 03 00 00 71 03 00 00 76 03 00 00 7b 03 00 00 7f 03 00 00 84 03 00 00 88 03 00 00 8c 03 00 00 91 03 00 00 95 03 00 00 99 03 00 00 9e 03 00 00 a2 03 00 00 a6 03 00 00 ab 03 00 00 af 03 00 00 b3 03 00 00 b7 03 00 00 bb 03 00 00 bf 03 00 00 c4 03 00 00 c8 03 00 00 cc 03 00 00 d0 03 00 00 d4 03 00 00 d8 03 00 00 dc 03 00 00 e0 03 00 00 e4 03 00 00 e8 03 00 00 eb 03 00 00 ef 03 00 00 f3 03 00 00 f7 03 00 00 fb 03 00 00 ff 03 00 00 06 00 00 00 00 00 00 00 32 00 00 00 5a 00 00 00 78 00 00 00 97 00 00 00 b4 00 00 00 cc 00 00 00 e5 00 00 00 fc 00 00 00 14 01 00 00 2c 01 00 00 42 01 00 00 56 01 00 00 67 01 00 00 76 01 00 00 83 01 00 00 8e 01 00 00 9a 01 00 00 a6 01 00 00 b1 01 00 00 bc 01 00 00 c6 01 00 00 cf 01 00 00 d8 01 00 00 e1 01 00 00 ea 01 00 00 f2 01 00 00 fb 01 00 00 03 02 00 00 0b 02 00 00 12 02 00 00 1a 02 00 00 21 02 00 00 28 02 00 00 2f 02 00 00 36 02 00 00 3d 02 00 00 43 02 00 00 4a 02 00 00 50 02 00 00 57 02 00 00 5d 02 00 00 63 02 00 00 69 02 00 00 6e 02 00 00 74 02 00 00 79 02 00 00 7f 02 00 00 84 02 00 00 8a 02 00 00 90 02 00 00 96 02 00 00 9b 02 00 00 a1 02 00 00 a7 02 00 00 ac 02 00 00 b2 02 00 00 b7 02 00 00 bd 02 00 00 c2 02 00 00 c8 02 00 00 cd 02 00 00 d2 02 00 00 d7 02 00 00 dd 02 00 00 e2 02 00 00 e7 02 00 00 ec 02 00 00 f2 02 00 00 f7 02 00 00 fc 02 00 00 01 03 00 00 06 03 00 00 0b 03 00 00 11 03 00 00 16 03 00 00 1b 03 00 00 20 03 00 00 25 03 00 00 2a 03 00 00 2f 03 00 00 34 03 00 00 38 03 00 00 3d 03 00 00 42 03 00 00 47 03 00 00 4c 03 00 00 51 03 00 00 55 03 00 00 5a 03 00 00 5f 03 00 00 63 03 00 00 68 03 00 00 6d 03 00 00 71 03 00 00 76 03 00 00 7b 03 00 00 7f 03 00 00 84 03 00 00 88 03 00 00 8c 03 00 00 91 03 00 00 95 03 00 00 99 03 00 00 9e 03 00 00 a2 03 00 00 a6 03 00 00 ab 03 00 00 af 03 00 00 b3 03 00 00 b7 03 00 00 bb 03 00 00 bf 03 00 00 c4 03 00 00 c8 03 00 00 cc 03 00 00 d0 03 00 00 d4 03 00 00 d8 03 00 00 dc 03 00 00 e0 03 00 00 e4 03 00 00 e8 03 00 00 eb 03 00 00 ef 03 00 00 f3 03 00 00 f7 03 00 00 fb 03 00 00 ff 03 00 00 04 00 00 00 00 00 00 00 32 00 00 00 5a 00 00 00 78 00 00 00 97 00 00 00 b4 00 00 00 cc 00 00 00 e5 00 00 00 fc 00 00 00 14 01 00 00 2c 01 00 00 42 01 00 00 56 01 00 00 67 01 00 00 76 01 00 00 83 01 00 00 8e 01 00 00 9a 01 00 00 a6 01 00 00 b1 01 00 00 bc 01 00 00 c6 01 00 00 cf 01 00 00 d8 01 00 00 e1 01 00 00 ea 01 00 00 f2 01 00 00 fb 01 00 00 03 02 00 00 0b 02 00 00 12 02 00 00 1a 02 00 00 21 02 00 00 28 02 00 00 2f 02 00 00 36 02 00 00 3d 02 00 00 43 02 00 00 4a 02 00 00 50 02 00 00 57 02 00 00 5d 02 00 00 63 02 00 00 69 02 00 00 6e 02 00 00 74 02 00 00 79 02 00 00 7f 02 00 00 84 02 00 00 8a 02 00 00 90 02 00 00 96 02 00 00 9b 02 00 00 a1 02 00 00 a7 02 00 00 ac 02 00 00 b2 02 00 00 b7 02 00 00 bd 02 00 00 c2 02 00 00 c8 02 00 00 cd 02 00 00 d2 02 00 00 d7 02 00 00 dd 02 00 00 e2 02 00 00 e7 02 00 00 ec 02 00 00 f2 02 00 00 f7 02 00 00 fc 02 00 00 01 03 00 00 06 03 00 00 0b 03 00 00 11 03 00 00 16 03 00 00 1b 03 00 00 20 03 00 00 25 03 00 00 2a 03 00 00 2f 03 00 00 34 03 00 00 38 03 00 00 3d 03 00 00 42 03 00 00 47 03 00 00 4c 03 00 00 51 03 00 00 55 03 00 00 5a 03 00 00 5f 03 00 00 63 03 00 00 68 03 00 00 6d 03 00 00 71 03 00 00 76 03 00 00 7b 03 00 00 7f 03 00 00 84 03 00 00 88 03 00 00 8c 03 00 00 91 03 00 00 95 03 00 00 99 03 00 00 9e 03 00 00 a2 03 00 00 a6 03 00 00 ab 03 00 00 af 03 00 00 b3 03 00 00 b7 03 00 00 bb 03 00 00 bf 03 00 00 c4 03 00 00 c8 03 00 00 cc 03 00 00 d0 03 00 00 d4 03 00 00 d8 03 00 00 dc 03 00 00 e0 03 00 00 e4 03 00 00 e8 03 00 00 eb 03 00 00 ef 03 00 00 f3 03 00 00 f7 03 00 00 fb 03 00 00 ff 03 00 00];
		};
		iq_ccm {
			size = [40 02 00 00];
			data = [00 00 00 00 ba 01 a0 ff a7 ff a7 ff f0 01 6a ff 0c 00 38 ff bb 01 80 80 80 80 80 80 80 80 80 80 80 80 80 80 80 80 80 80 80 80 80 80 80 80 00 00 00 00 00 00 00 00 00 00 00 00 00 00 00 00 00 00 00 00 00 00 00 00 00 00 00 00 00 00 00 00 00 00 00 00 00 00 00 00 00 00 00 00 00 00 00 00 00 00 00 00 00 00 00 00 00 00 00 00 00 00 00 00 00 00 00 00 00 00 00 00 00 00 00 00 00 00 00 00 00 00 00 00 00 00 00 00 00 00 00 00 00 00 00 00 00 00 64 19 00 00 70 02 28 ff 68 ff 58 ff 8f 02 19 ff eb ff db fe 3a 02 80 80 80 80 80 80 80 80 80 80 80 80 80 80 80 80 80 80 80 80 80 80 80 80 00 00 0a 00 00 00 0a 00 00 00 00 00 00 00 00 00 00 00 00 00 00 00 00 00 00 00 00 00 00 00 00 00 00 00 00 00 00 00 00 00 00 00 00 00 00 00 00 00 00 00 00 00 00 00 00 00 00 00 00 00 00 00 00 00 00 00 00 00 00 00 00 00 00 00 00 00 00 00 00 00 00 00 00 00 00 00 00 00 00 00 00 00 00 00 00 00 00 00 ac 0d 00 00 db 01 73 ff b2 ff 39 ff 12 02 b5 ff cd ff 88 fe ab 02 80 80 80 80 80 80 80 80 80 80 80 80 80 80 80 80 80 80 80 80 80 80 80 80 00 00 00 00 00 00 00 00 00 00 00 00 00 00 00 00 00 00 00 00 00 00 00 00 00 00 00 00 00 00 00 00 00 00 00 00 00 00 00 00 00 00 00 00 00 00 00 00 00 00 00 00 00 00 00 00 00 00 00 00 00 00 00 00 00 00 00 00 00 00 00 00 00 00 00 00 00 00 00 00 00 00 00 00 00 00 00 00 00 00 00 00 00 00 00 00 00 00 f0 0a 00 00 31 01 0e 00 c0 ff 1c ff 04 02 e1 ff 76 ff e3 fd a7 03 80 80 80 80 80 80 80 80 80 80 80 80 80 80 80 80 80 80 80 80 80 80 80 80 00 00 00 00 00 00 00 00 00 00 00 00 00 00 00 00 00 00 00 00 00 00 00 00 00 00 00 00 00 00 00 00 00 00 00 00 00 00 00 00 00 00 00 00 00 00 00 00 00 00 00 00 00 00 00 00 00 00 00 00 00 00 00 00 00 00 00 00 00 00 00 00 00 00 00 00 00 00 00 00 00 00 00 00 00 00 00 00 00 00 00 00 00 00 00 00 00 00];
		};
		iq_color {
			size = [ec 06 00 00];
			data = [00 00 00 00 80 80 40 10 00 00 00 00 00 00 00 00 00 00 00 00 00 14 0f 0a 05 00 00 00 00 00 00 00 00 00 05 0a 0f 00 00 00 80 00 00 00 80 00 00 00 80 00 00 00 80 00 00 00 80 00 00 00 80 00 00 00 80 00 00 00 80 00 00 00 80 00 00 00 80 00 00 00 80 00 00 00 80 00 00 00 80 00 00 00 80 00 00 00 80 00 00 00 80 00 00 00 80 00 00 00 b4 80 40 10 00 00 00 00 00 00 00 00 00 00 00 00 00 14 0f 0a 05 00 00 00 00 00 00 00 00 00 05 0a 0f 00 00 00 80 00 00 00 80 00 00 00 80 00 00 00 80 00 00 00 80 00 00 00 80 00 00 00 80 00 00 00 80 00 00 00 80 00 00 00 80 00 00 00 80 00 00 00 80 00 00 00 80 00 00 00 80 00 00 00 80 00 00 00 80 00 00 00 80 00 00 00 96 80 40 10 00 00 00 00 00 00 00 00 00 00 00 00 00 14 0f 0a 05 00 00 00 00 00 00 00 00 00 05 0a 0f 00 00 00 80 00 00 00 80 00 00 00 80 00 00 00 80 00 00 00 80 00 00 00 80 00 00 00 80 00 00 00 80 00 00 00 80 00 00 00 80 00 00 00 80 00 00 00 80 00 00 00 80 00 00 00 80 00 00 00 80 00 00 00 80 00 00 00 80 00 00 00 96 80 40 10 00 00 00 00 00 00 00 00 00 00 00 00 00 14 0f 0a 05 00 00 00 00 00 00 00 00 00 05 0a 0f 00 00 00 80 00 00 00 80 00 00 00 80 00 00 00 80 00 00 00 80 00 00 00 80 00 00 00 80 00 00 00 80 00 00 00 80 00 00 00 80 00 00 00 80 00 00 00 80 00 00 00 80 00 00 00 80 00 00 00 80 00 00 00 80 00 00 00 80 00 00 00 8c 80 40 10 00 00 00 00 00 00 00 00 00 00 00 00 00 00 00 00 00 00 00 00 00 00 00 00 00 00 05 0a 0f 00 00 00 80 00 00 00 80 00 00 00 80 00 00 00 80 00 00 00 80 00 00 00 80 00 00 00 80 00 00 00 80 00 00 00 80 00 00 00 80 00 00 00 80 00 00 00 80 00 00 00 80 00 00 00 80 00 00 00 80 00 00 00 80 00 00 00 80 00 00 00 6e c4 86 5a 2c 0c 00 00 00 00 00 00 00 00 00 00 00 14 0f 0a 05 00 00 00 00 00 00 00 00 00 05 0a 0f 00 00 00 80 00 00 00 80 00 00 00 80 00 00 00 80 00 00 00 80 00 00 00 80 00 00 00 80 00 00 00 80 00 00 00 80 00 00 00 80 00 00 00 80 00 00 00 80 00 00 00 80 00 00 00 80 00 00 00 80 00 00 00 80 00 00 00 80 00 00 00 78 e7 bb 8d 58 27 0c 00 00 00 00 00 00 00 00 00 00 1e 0f 0a 05 00 00 00 00 00 00 00 00 00 05 0a 0f 00 00 00 80 00 00 00 80 00 00 00 80 00 00 00 80 00 00 00 80 00 00 00 80 00 00 00 80 00 00 00 80 00 00 00 80 00 00 00 80 00 00 00 80 00 00 00 80 00 00 00 80 00 00 00 80 00 00 00 80 00 00 00 80 00 00 00 80 00 00 00 64 e7 bb 8d 58 27 0c 00 00 00 00 00 00 00 00 00 00 1e 0f 0a 05 00 00 00 00 00 00 00 00 00 05 0a 0f 00 00 00 80 00 00 00 80 00 00 00 80 00 00 00 80 00 00 00 80 00 00 00 80 00 00 00 80 00 00 00 80 00 00 00 80 00 00 00 80 00 00 00 80 00 00 00 80 00 00 00 80 00 00 00 80 00 00 00 80 00 00 00 80 00 00 00 80 00 00 00 76 80 43 10 00 00 00 00 00 00 00 00 00 00 00 00 00 14 0f 0a 05 00 00 00 00 00 00 00 00 00 05 0a 0f 00 00 00 80 00 00 00 80 00 00 00 80 00 00 00 80 00 00 00 80 00 00 00 80 00 00 00 80 00 00 00 80 00 00 00 80 00 00 00 80 00 00 00 80 00 00 00 80 00 00 00 80 00 00 00 80 00 00 00 80 00 00 00 80 00 00 00 80 00 00 00 80 80 40 10 00 00 00 00 00 00 00 00 00 00 00 00 00 14 0f 0a 05 00 00 00 00 00 00 00 00 00 05 0a 0f 00 00 00 80 00 00 00 80 00 00 00 80 00 00 00 80 00 00 00 80 00 00 00 80 00 00 00 80 00 00 00 80 00 00 00 80 00 00 00 80 00 00 00 80 00 00 00 80 00 00 00 80 00 00 00 80 00 00 00 80 00 00 00 80 00 00 00 80 00 00 00 80 80 40 10 00 00 00 00 00 00 00 00 00 00 00 00 00 14 0f 0a 05 00 00 00 00 00 00 00 00 00 05 0a 0f 00 00 00 80 00 00 00 80 00 00 00 80 00 00 00 80 00 00 00 80 00 00 00 80 00 00 00 80 00 00 00 80 00 00 00 80 00 00 00 80 00 00 00 80 00 00 00 80 00 00 00 80 00 00 00 80 00 00 00 80 00 00 00 80 00 00 00 80 00 00 00 80 80 40 10 00 00 00 00 00 00 00 00 00 00 00 00 00 14 0f 0a 05 00 00 00 00 00 00 00 00 00 05 0a 0f 00 00 00 80 00 00 00 80 00 00 00 80 00 00 00 80 00 00 00 80 00 00 00 80 00 00 00 80 00 00 00 80 00 00 00 80 00 00 00 80 00 00 00 80 00 00 00 80 00 00 00 80 00 00 00 80 00 00 00 80 00 00 00 80 00 00 00 80 00 00 00 80 80 40 10 00 00 00 00 00 00 00 00 00 00 00 00 00 14 0f 0a 05 00 00 00 00 00 00 00 00 00 05 0a 0f 00 00 00 80 00 00 00 80 00 00 00 80 00 00 00 80 00 00 00 80 00 00 00 80 00 00 00 80 00 00 00 80 00 00 00 80 00 00 00 80 00 00 00 80 00 00 00 80 00 00 00 80 00 00 00 80 00 00 00 80 00 00 00 80 00 00 00 80 00 00 00 80 80 40 10 00 00 00 00 00 00 00 00 00 00 00 00 00 14 0f 0a 05 00 00 00 00 00 00 00 00 00 05 0a 0f 00 00 00 80 00 00 00 80 00 00 00 80 00 00 00 80 00 00 00 80 00 00 00 80 00 00 00 80 00 00 00 80 00 00 00 80 00 00 00 80 00 00 00 80 00 00 00 80 00 00 00 80 00 00 00 80 00 00 00 80 00 00 00 80 00 00 00 80 00 00 00 80 80 40 10 00 00 00 00 00 00 00 00 00 00 00 00 00 14 0f 0a 05 00 00 00 00 00 00 00 00 00 05 0a 0f 00 00 00 80 00 00 00 80 00 00 00 80 00 00 00 80 00 00 00 80 00 00 00 80 00 00 00 80 00 00 00 80 00 00 00 80 00 00 00 80 00 00 00 80 00 00 00 80 00 00 00 80 00 00 00 80 00 00 00 80 00 00 00 80 00 00 00 80 00 00 00 80 80 40 10 00 00 00 00 00 00 00 00 00 00 00 00 00 14 0f 0a 05 00 00 00 00 00 00 00 00 00 05 0a 0f 00 00 00 80 00 00 00 80 00 00 00 80 00 00 00 80 00 00 00 80 00 00 00 80 00 00 00 80 00 00 00 80 00 00 00 80 00 00 00 80 00 00 00 80 00 00 00 80 00 00 00 80 00 00 00 80 00 00 00 80 00 00 00 80 00 00 00 80 00 00 00 80 80 40 10 00 00 00 00 00 00 00 00 00 00 00 00 00 14 0f 0a 05 00 00 00 00 00 00 00 00 00 05 0a 0f 00 00 00 80 00 00 00 80 00 00 00 80 00 00 00 80 00 00 00 80 00 00 00 80 00 00 00 80 00 00 00 80 00 00 00 80 00 00 00 80 00 00 00 80 00 00 00 80 00 00 00 80 00 00 00 80 00 00 00 80 00 00 00 80 00 00 00 80 00 00 00];
		};
		iq_contrast {
			size = [b0 00 00 00];
			data = [00 00 00 00 80 00 00 00 00 00 00 00 00 00 78 00 05 0a 0f 14 19 19 19 19 78 00 05 0a 0f 14 19 19 19 19 78 00 05 0a 0f 14 19 19 19 19 78 00 05 0a 0f 14 19 19 19 19 78 00 05 0a 0f 14 19 19 19 19 78 00 05 0a 0f 14 19 19 19 19 78 00 05 0a 0f 14 19 19 19 19 80 14 14 14 14 14 14 14 14 14 87 0a 0a 0a 0a 0a 0a 0a 0a 0a 87 0a 0a 0a 0a 0a 0a 0a 0a 0a 84 0a 0a 0a 0a 0a 0a 0a 0a 0a 84 0a 0a 0a 0a 0a 0a 0a 0a 0a 80 0a 0a 0a 0a 0a 0a 0a 0a 0a 80 0a 0a 0a 0a 0a 0a 0a 0a 0a 80 0a 0a 0a 0a 0a 0a 0a 0a 0a 80 0a 0a 0a 0a 0a 0a 0a 0a 0a 00 00];
		};
		iq_edge {
			size = [14 05 00 00];
			data = [01 00 00 00 00 00 00 00 80 00 00 00 00 00 00 00 00 43 6a 97 c1 ee ff ff ff ff d7 c1 aa 9d 90 8a 20 2d 35 37 3d 3c 3c 3c 3c 3c 3c 3c 3c 34 2c 26 80 80 80 80 80 80 80 80 80 80 80 80 80 80 80 80 80 80 80 80 80 80 80 80 40 00 00 00 80 00 00 00 80 00 00 00 08 00 00 00 00 00 00 00 00 00 00 00 10 00 00 00 28 00 00 00 f0 00 00 00 00 01 00 00 00 01 00 00 00 00 00 00 80 00 00 00 00 00 00 00 02 00 00 00 00 00 00 00 00 02 00 00 00 00 00 00 05 00 00 00 96 00 00 00 d2 00 00 00 0c 00 00 00 08 00 00 00 00 00 00 00 10 00 00 00 32 00 00 00 c8 00 00 00 00 01 00 00 00 01 00 00 06 00 00 00 90 01 00 00 00 00 00 00 05 00 00 00 00 00 00 00 a8 02 00 00 00 00 00 00 05 00 00 00 96 00 00 00 c8 00 00 00 0c 00 00 00 08 00 00 00 00 00 00 00 10 00 00 00 50 00 00 00 a0 00 00 00 00 01 00 00 00 01 00 00 08 00 00 00 e0 01 00 00 00 00 00 00 05 00 00 00 00 00 00 00 80 02 00 00 00 00 00 00 05 00 00 00 8c 00 00 00 b4 00 00 00 0c 00 00 00 08 00 00 00 00 00 00 00 10 00 00 00 5a 00 00 00 b4 00 00 00 00 01 00 00 00 01 00 00 0a 00 00 00 00 01 00 00 00 00 00 00 05 00 00 00 08 00 00 00 00 02 00 00 00 00 00 00 05 00 00 00 78 00 00 00 8c 00 00 00 0c 00 00 00 0c 00 00 00 04 00 00 00 10 00 00 00 78 00 00 00 be 00 00 00 00 01 00 00 00 01 00 00 08 00 00 00 00 01 00 00 00 00 00 00 05 00 00 00 06 00 00 00 00 02 00 00 00 00 00 00 05 00 00 00 64 00 00 00 78 00 00 00 0a 00 00 00 04 00 00 00 00 00 00 00 0c 00 00 00 68 00 00 00 dc 00 00 00 00 01 00 00 00 01 00 00 00 00 00 00 00 01 00 00 03 00 00 00 05 00 00 00 00 00 00 00 00 02 00 00 00 00 00 00 05 00 00 00 82 00 00 00 5a 00 00 00 04 00 00 00 04 00 00 00 00 00 00 00 0c 00 00 00 a0 00 00 00 2c 01 00 00 00 01 00 00 00 01 00 00 19 00 00 00 b4 00 00 00 04 00 00 00 04 00 00 00 00 00 00 00 00 01 00 00 03 00 00 00 02 00 00 00 50 00 00 00 40 00 00 00 03 00 00 00 00 00 00 00 00 00 00 00 0c 00 00 00 f0 00 00 00 40 01 00 00 00 01 00 00 00 01 00 00 1e 00 00 00 96 00 00 00 04 00 00 00 03 00 00 00 00 00 00 00 00 01 00 00 04 00 00 00 02 00 00 00 5a 00 00 00 82 00 00 00 03 00 00 00 03 00 00 00 04 00 00 00 09 00 00 00 2c 01 00 00 81 01 00 00 00 01 00 00 00 01 00 00 00 00 00 00 50 00 00 00 03 00 00 00 00 00 00 00 00 00 00 00 00 01 00 00 03 00 00 00 00 00 00 00 46 00 00 00 46 00 00 00 00 00 00 00 00 00 00 00 00 00 00 00 04 00 00 00 96 00 00 00 2c 01 00 00 00 01 00 00 00 01 00 00 00 00 00 00 50 00 00 00 03 00 00 00 04 00 00 00 00 00 00 00 00 02 00 00 00 00 00 00 05 00 00 00 40 00 00 00 40 00 00 00 00 00 00 00 00 00 00 00 00 00 00 00 04 00 00 00 96 00 00 00 2c 01 00 00 00 01 00 00 00 01 00 00 00 00 00 00 50 00 00 00 03 00 00 00 04 00 00 00 00 00 00 00 00 02 00 00 00 00 00 00 05 00 00 00 4b 00 00 00 6e 00 00 00 00 00 00 00 00 00 00 00 00 00 00 00 04 00 00 00 4d 00 00 00 09 01 00 00 00 01 00 00 00 01 00 00 00 00 00 00 80 00 00 00 03 00 00 00 02 00 00 00 00 00 00 00 00 02 00 00 00 00 00 00 05 00 00 00 4b 00 00 00 50 00 00 00 00 00 00 00 00 00 00 00 00 00 00 00 04 00 00 00 4d 00 00 00 09 01 00 00 00 01 00 00 00 01 00 00 00 00 00 00 80 00 00 00 04 00 00 00 02 00 00 00 00 00 00 00 00 02 00 00 00 00 00 00 05 00 00 00 3c 00 00 00 3c 00 00 00 00 00 00 00 00 00 00 00 00 00 00 00 04 00 00 00 93 02 00 00 f5 02 00 00 00 01 00 00 00 01 00 00 00 00 00 00 80 00 00 00 05 00 00 00 02 00 00 00 00 00 00 00 00 02 00 00 00 00 00 00 05 00 00 00 3c 00 00 00 3c 00 00 00 00 00 00 00 00 00 00 00 00 00 00 00 04 00 00 00 93 02 00 00 f5 02 00 00 00 01 00 00 00 01 00 00 00 00 00 00 80 00 00 00 05 00 00 00 02 00 00 00 00 00 00 00 00 02 00 00 00 00 00 00 05 00 00 00 3c 00 00 00 3c 00 00 00 00 00 00 00 00 00 00 00 00 00 00 00 04 00 00 00 93 02 00 00 f5 02 00 00 00 01 00 00 00 01 00 00 00 00 00 00 80 00 00 00 05 00 00 00 02 00 00 00 00 00 00 00 00 02 00 00 00 00 00 00 05 00 00 00 3c 00 00 00 3c 00 00 00 00 00 00 00 00 00 00 00 00 00 00 00 04 00 00 00 93 02 00 00 f5 02 00 00 00 01 00 00 00 01 00 00 00 00 00 00 80 00 00 00 05 00 00 00 02 00 00 00 00 00 00 00 00 02 00 00 00 00 00 00 05 00 00 00];
		};
		iq_3dnr {
			size = [50 1e 00 00];
			data = [01 00 00 00 00 00 00 00 40 00 00 00 40 00 00 00 00 00 00 00 80 00 00 00 80 00 00 00 80 00 00 00 c8 00 00 00 c8 00 00 00 04 00 00 00 04 00 00 00 03 00 00 00 04 00 00 00 04 00 00 00 04 00 00 00 04 00 00 00 04 00 00 00 05 00 00 00 05 00 00 00 06 00 00 00 06 00 00 00 07 00 00 00 07 00 00 00 08 00 00 00 08 00 00 00 80 00 00 00 04 00 00 00 00 00 00 00 00 00 00 00 00 00 00 00 00 00 00 00 00 00 00 00 00 00 00 00 00 00 00 00 00 00 00 00 00 00 00 00 00 00 00 00 00 00 00 00 00 00 00 00 00 00 00 00 00 00 00 00 00 00 00 00 00 00 00 00 00 00 00 00 00 00 00 00 00 00 00 00 00 00 00 00 00 00 00 00 00 00 00 00 00 00 00 00 00 00 00 00 00 00 00 00 00 00 00 00 00 00 00 00 00 00 00 00 00 00 00 00 00 00 00 00 00 00 00 00 00 00 00 00 08 00 00 00 10 00 00 00 04 00 00 00 b4 00 00 00 e6 00 00 00 06 00 00 00 01 00 00 00 01 00 00 00 10 00 00 00 20 00 00 00 30 00 00 00 40 00 00 00 80 00 00 00 40 00 00 00 00 01 00 00 00 01 00 00 10 00 00 00 10 00 00 00 10 00 00 00 10 00 00 00 10 00 00 00 10 00 00 00 10 00 00 00 10 00 00 00 10 00 00 00 10 00 00 00 10 00 00 00 10 00 00 00 08 00 00 00 10 00 00 00 40 00 00 00 40 00 00 00 10 00 00 00 08 00 00 00 08 00 00 00 10 00 00 00 18 00 00 00 20 00 00 00 00 00 00 00 06 00 00 00 0c 00 00 00 18 00 00 00 28 00 00 00 4c 00 00 00 60 00 00 00 70 00 00 00 00 00 00 00 06 00 00 00 0c 00 00 00 18 00 00 00 28 00 00 00 4c 00 00 00 60 00 00 00 70 00 00 00 80 00 00 00 40 00 00 00 10 00 00 00 10 00 00 00 00 00 00 00 20 00 00 00 20 00 00 00 20 00 00 00 70 00 00 00 70 00 00 00 04 00 00 00 04 00 00 00 03 00 00 00 04 00 00 00 04 00 00 00 04 00 00 00 04 00 00 00 04 00 00 00 04 00 00 00 04 00 00 00 05 00 00 00 06 00 00 00 06 00 00 00 07 00 00 00 07 00 00 00 08 00 00 00 8c 00 00 00 03 00 00 00 c8 00 00 00 dc 00 00 00 dc 00 00 00 c8 00 00 00 c8 00 00 00 c8 00 00 00 c8 00 00 00 c8 00 00 00 0b 00 00 00 0a 00 00 00 0a 00 00 00 0a 00 00 00 09 00 00 00 09 00 00 00 09 00 00 00 09 00 00 00 82 00 00 00 82 00 00 00 82 00 00 00 82 00 00 00 78 00 00 00 78 00 00 00 78 00 00 00 78 00 00 00 0f 00 00 00 19 00 00 00 19 00 00 00 0f 00 00 00 0f 00 00 00 0f 00 00 00 0f 00 00 00 0f 00 00 00 08 00 00 00 0c 00 00 00 05 00 00 00 b4 00 00 00 96 00 00 00 06 00 00 00 01 00 00 00 01 00 00 00 10 00 00 00 20 00 00 00 30 00 00 00 40 00 00 00 40 00 00 00 40 00 00 00 f4 01 00 00 20 03 00 00 10 00 00 00 10 00 00 00 10 00 00 00 10 00 00 00 10 00 00 00 10 00 00 00 10 00 00 00 10 00 00 00 10 00 00 00 10 00 00 00 10 00 00 00 10 00 00 00 04 00 00 00 20 00 00 00 40 00 00 00 40 00 00 00 10 00 00 00 08 00 00 00 06 00 00 00 08 00 00 00 0c 00 00 00 28 00 00 00 00 00 00 00 08 00 00 00 0e 00 00 00 18 00 00 00 23 00 00 00 31 00 00 00 49 00 00 00 70 00 00 00 00 00 00 00 0d 00 00 00 16 00 00 00 26 00 00 00 34 00 00 00 49 00 00 00 5d 00 00 00 70 00 00 00 80 00 00 00 40 00 00 00 18 00 00 00 18 00 00 00 00 00 00 00 30 00 00 00 30 00 00 00 30 00 00 00 b4 00 00 00 b4 00 00 00 04 00 00 00 04 00 00 00 03 00 00 00 04 00 00 00 04 00 00 00 04 00 00 00 04 00 00 00 04 00 00 00 04 00 00 00 04 00 00 00 05 00 00 00 06 00 00 00 06 00 00 00 07 00 00 00 07 00 00 00 08 00 00 00 7f 00 00 00 05 00 00 00 c8 00 00 00 dc 00 00 00 dc 00 00 00 c8 00 00 00 c8 00 00 00 c8 00 00 00 c8 00 00 00 c8 00 00 00 0c 00 00 00 0d 00 00 00 0c 00 00 00 0a 00 00 00 0a 00 00 00 0a 00 00 00 09 00 00 00 09 00 00 00 04 01 00 00 18 01 00 00 18 01 00 00 0e 01 00 00 fa 00 00 00 fa 00 00 00 fa 00 00 00 fa 00 00 00 12 00 00 00 1c 00 00 00 1c 00 00 00 17 00 00 00 12 00 00 00 12 00 00 00 12 00 00 00 12 00 00 00 08 00 00 00 0c 00 00 00 05 00 00 00 aa 00 00 00 aa 00 00 00 06 00 00 00 01 00 00 00 01 00 00 00 10 00 00 00 20 00 00 00 30 00 00 00 40 00 00 00 40 00 00 00 20 00 00 00 f4 01 00 00 20 03 00 00 10 00 00 00 10 00 00 00 10 00 00 00 10 00 00 00 10 00 00 00 10 00 00 00 10 00 00 00 10 00 00 00 10 00 00 00 10 00 00 00 10 00 00 00 10 00 00 00 04 00 00 00 30 00 00 00 48 00 00 00 48 00 00 00 10 00 00 00 08 00 00 00 06 00 00 00 08 00 00 00 0c 00 00 00 12 00 00 00 00 00 00 00 08 00 00 00 0c 00 00 00 14 00 00 00 20 00 00 00 2c 00 00 00 3f 00 00 00 54 00 00 00 00 00 00 00 0d 00 00 00 16 00 00 00 26 00 00 00 34 00 00 00 49 00 00 00 5d 00 00 00 70 00 00 00 80 00 00 00 40 00 00 00 20 00 00 00 20 00 00 00 00 00 00 00 40 00 00 00 40 00 00 00 40 00 00 00 dc 00 00 00 dc 00 00 00 04 00 00 00 04 00 00 00 03 00 00 00 04 00 00 00 04 00 00 00 04 00 00 00 04 00 00 00 04 00 00 00 04 00 00 00 04 00 00 00 05 00 00 00 06 00 00 00 06 00 00 00 07 00 00 00 07 00 00 00 08 00 00 00 a0 00 00 00 03 00 00 00 7c 01 00 00 90 01 00 00 90 01 00 00 7c 01 00 00 7c 01 00 00 7c 01 00 00 7c 01 00 00 7c 01 00 00 0b 00 00 00 10 00 00 00 12 00 00 00 0e 00 00 00 0b 00 00 00 0b 00 00 00 0b 00 00 00 0b 00 00 00 04 01 00 00 04 01 00 00 18 01 00 00 40 01 00 00 04 01 00 00 04 01 00 00 04 01 00 00 04 01 00 00 12 00 00 00 12 00 00 00 12 00 00 00 12 00 00 00 12 00 00 00 12 00 00 00 0d 00 00 00 0d 00 00 00 08 00 00 00 0c 00 00 00 05 00 00 00 96 00 00 00 96 00 00 00 06 00 00 00 01 00 00 00 01 00 00 00 10 00 00 00 20 00 00 00 30 00 00 00 40 00 00 00 40 00 00 00 40 00 00 00 58 02 00 00 20 03 00 00 10 00 00 00 10 00 00 00 10 00 00 00 10 00 00 00 10 00 00 00 10 00 00 00 10 00 00 00 10 00 00 00 10 00 00 00 10 00 00 00 10 00 00 00 10 00 00 00 08 00 00 00 50 00 00 00 80 00 00 00 64 00 00 00 18 00 00 00 18 00 00 00 08 00 00 00 0a 00 00 00 0e 00 00 00 18 00 00 00 00 00 00 00 06 00 00 00 0c 00 00 00 1e 00 00 00 2e 00 00 00 41 00 00 00 5a 00 00 00 70 00 00 00 00 00 00 00 08 00 00 00 10 00 00 00 20 00 00 00 2e 00 00 00 3f 00 00 00 55 00 00 00 70 00 00 00 80 00 00 00 40 00 00 00 30 00 00 00 30 00 00 00 00 00 00 00 60 00 00 00 60 00 00 00 60 00 00 00 f0 00 00 00 f0 00 00 00 04 00 00 00 04 00 00 00 03 00 00 00 04 00 00 00 04 00 00 00 04 00 00 00 04 00 00 00 04 00 00 00 04 00 00 00 04 00 00 00 05 00 00 00 06 00 00 00 06 00 00 00 07 00 00 00 07 00 00 00 08 00 00 00 a0 00 00 00 03 00 00 00 7c 01 00 00 90 01 00 00 90 01 00 00 7c 01 00 00 7c 01 00 00 7c 01 00 00 7c 01 00 00 7c 01 00 00 0a 00 00 00 0f 00 00 00 11 00 00 00 0d 00 00 00 0a 00 00 00 0a 00 00 00 0a 00 00 00 0a 00 00 00 04 01 00 00 04 01 00 00 18 01 00 00 40 01 00 00 04 01 00 00 04 01 00 00 04 01 00 00 04 01 00 00 14 00 00 00 14 00 00 00 14 00 00 00 14 00 00 00 14 00 00 00 14 00 00 00 0f 00 00 00 0f 00 00 00 08 00 00 00 0c 00 00 00 05 00 00 00 96 00 00 00 96 00 00 00 06 00 00 00 01 00 00 00 01 00 00 00 20 00 00 00 30 00 00 00 34 00 00 00 40 00 00 00 40 00 00 00 40 00 00 00 58 02 00 00 20 03 00 00 10 00 00 00 10 00 00 00 10 00 00 00 10 00 00 00 10 00 00 00 10 00 00 00 10 00 00 00 10 00 00 00 10 00 00 00 10 00 00 00 10 00 00 00 10 00 00 00 0a 00 00 00 64 00 00 00 c8 00 00 00 78 00 00 00 20 00 00 00 14 00 00 00 0c 00 00 00 12 00 00 00 18 00 00 00 20 00 00 00 00 00 00 00 06 00 00 00 0c 00 00 00 10 00 00 00 1e 00 00 00 2c 00 00 00 4c 00 00 00 70 00 00 00 00 00 00 00 08 00 00 00 13 00 00 00 20 00 00 00 2e 00 00 00 3f 00 00 00 55 00 00 00 70 00 00 00 40 00 00 00 20 00 00 00 40 00 00 00 40 00 00 00 00 00 00 00 80 00 00 00 80 00 00 00 80 00 00 00 2c 01 00 00 2c 01 00 00 04 00 00 00 04 00 00 00 03 00 00 00 04 00 00 00 04 00 00 00 04 00 00 00 04 00 00 00 04 00 00 00 04 00 00 00 04 00 00 00 05 00 00 00 06 00 00 00 06 00 00 00 07 00 00 00 07 00 00 00 08 00 00 00 a8 00 00 00 04 00 00 00 7c 01 00 00 90 01 00 00 90 01 00 00 7c 01 00 00 7c 01 00 00 7c 01 00 00 7c 01 00 00 7c 01 00 00 0b 00 00 00 10 00 00 00 12 00 00 00 0e 00 00 00 0b 00 00 00 0b 00 00 00 0b 00 00 00 0b 00 00 00 09 01 00 00 09 01 00 00 1d 01 00 00 45 01 00 00 09 01 00 00 09 01 00 00 09 01 00 00 09 01 00 00 15 00 00 00 15 00 00 00 15 00 00 00 15 00 00 00 15 00 00 00 15 00 00 00 10 00 00 00 10 00 00 00 08 00 00 00 0c 00 00 00 08 00 00 00 96 00 00 00 96 00 00 00 06 00 00 00 01 00 00 00 01 00 00 00 10 00 00 00 20 00 00 00 30 00 00 00 40 00 00 00 20 00 00 00 20 00 00 00 58 02 00 00 20 03 00 00 10 00 00 00 10 00 00 00 10 00 00 00 10 00 00 00 10 00 00 00 10 00 00 00 10 00 00 00 10 00 00 00 10 00 00 00 10 00 00 00 10 00 00 00 10 00 00 00 00 00 00 00 64 00 00 00 c8 00 00 00 ff 00 00 00 14 00 00 00 14 00 00 00 0c 00 00 00 12 00 00 00 18 00 00 00 20 00 00 00 00 00 00 00 06 00 00 00 0d 00 00 00 16 00 00 00 21 00 00 00 31 00 00 00 4c 00 00 00 70 00 00 00 00 00 00 00 08 00 00 00 13 00 00 00 20 00 00 00 2e 00 00 00 3f 00 00 00 55 00 00 00 70 00 00 00 40 00 00 00 20 00 00 00 60 00 00 00 60 00 00 00 00 00 00 00 a0 00 00 00 a0 00 00 00 a0 00 00 00 68 01 00 00 68 01 00 00 04 00 00 00 04 00 00 00 03 00 00 00 04 00 00 00 04 00 00 00 04 00 00 00 04 00 00 00 04 00 00 00 04 00 00 00 04 00 00 00 05 00 00 00 06 00 00 00 06 00 00 00 07 00 00 00 07 00 00 00 08 00 00 00 a8 00 00 00 04 00 00 00 7c 01 00 00 90 01 00 00 90 01 00 00 7c 01 00 00 7c 01 00 00 7c 01 00 00 7c 01 00 00 7c 01 00 00 0d 00 00 00 12 00 00 00 14 00 00 00 10 00 00 00 0d 00 00 00 0d 00 00 00 0d 00 00 00 0d 00 00 00 4a 01 00 00 4a 01 00 00 5e 01 00 00 86 01 00 00 4a 01 00 00 4a 01 00 00 4a 01 00 00 4a 01 00 00 17 00 00 00 17 00 00 00 17 00 00 00 17 00 00 00 17 00 00 00 17 00 00 00 12 00 00 00 12 00 00 00 08 00 00 00 0a 00 00 00 08 00 00 00 96 00 00 00 96 00 00 00 06 00 00 00 01 00 00 00 01 00 00 00 20 00 00 00 30 00 00 00 34 00 00 00 40 00 00 00 20 00 00 00 20 00 00 00 20 03 00 00 20 03 00 00 10 00 00 00 10 00 00 00 10 00 00 00 10 00 00 00 18 00 00 00 14 00 00 00 10 00 00 00 10 00 00 00 10 00 00 00 10 00 00 00 10 00 00 00 10 00 00 00 00 00 00 00 64 00 00 00 c8 00 00 00 ff 00 00 00 20 00 00 00 18 00 00 00 0c 00 00 00 12 00 00 00 18 00 00 00 20 00 00 00 00 00 00 00 08 00 00 00 0c 00 00 00 13 00 00 00 1e 00 00 00 2c 00 00 00 3f 00 00 00 50 00 00 00 00 00 00 00 08 00 00 00 10 00 00 00 1b 00 00 00 26 00 00 00 31 00 00 00 42 00 00 00 50 00 00 00 20 00 00 00 20 00 00 00 60 00 00 00 60 00 00 00 00 00 00 00 a0 00 00 00 a0 00 00 00 a0 00 00 00 08 02 00 00 08 02 00 00 04 00 00 00 04 00 00 00 03 00 00 00 04 00 00 00 04 00 00 00 04 00 00 00 04 00 00 00 04 00 00 00 04 00 00 00 04 00 00 00 05 00 00 00 06 00 00 00 06 00 00 00 07 00 00 00 07 00 00 00 08 00 00 00 9e 00 00 00 03 00 00 00 7c 01 00 00 90 01 00 00 90 01 00 00 7c 01 00 00 7c 01 00 00 7c 01 00 00 7c 01 00 00 7c 01 00 00 0f 00 00 00 14 00 00 00 19 00 00 00 15 00 00 00 12 00 00 00 12 00 00 00 12 00 00 00 12 00 00 00 59 01 00 00 59 01 00 00 6d 01 00 00 95 01 00 00 59 01 00 00 59 01 00 00 59 01 00 00 59 01 00 00 19 00 00 00 19 00 00 00 19 00 00 00 19 00 00 00 19 00 00 00 19 00 00 00 14 00 00 00 14 00 00 00 08 00 00 00 0a 00 00 00 0b 00 00 00 96 00 00 00 96 00 00 00 0c 00 00 00 01 00 00 00 01 00 00 00 20 00 00 00 30 00 00 00 34 00 00 00 40 00 00 00 20 00 00 00 20 00 00 00 20 03 00 00 20 03 00 00 10 00 00 00 10 00 00 00 10 00 00 00 10 00 00 00 0a 00 00 00 0c 00 00 00 10 00 00 00 10 00 00 00 10 00 00 00 10 00 00 00 10 00 00 00 10 00 00 00 00 00 00 00 b4 00 00 00 b4 00 00 00 ff 00 00 00 24 00 00 00 12 00 00 00 0c 00 00 00 12 00 00 00 18 00 00 00 20 00 00 00 00 00 00 00 06 00 00 00 0c 00 00 00 14 00 00 00 1e 00 00 00 2c 00 00 00 3f 00 00 00 55 00 00 00 00 00 00 00 0c 00 00 00 13 00 00 00 21 00 00 00 2e 00 00 00 3f 00 00 00 55 00 00 00 70 00 00 00 10 00 00 00 10 00 00 00 64 00 00 00 64 00 00 00 00 00 00 00 40 01 00 00 40 01 00 00 40 01 00 00 e0 01 00 00 e0 01 00 00 04 00 00 00 04 00 00 00 03 00 00 00 04 00 00 00 04 00 00 00 04 00 00 00 04 00 00 00 04 00 00 00 04 00 00 00 04 00 00 00 05 00 00 00 06 00 00 00 06 00 00 00 07 00 00 00 07 00 00 00 08 00 00 00 c8 00 00 00 04 00 00 00 7c 01 00 00 90 01 00 00 90 01 00 00 7c 01 00 00 7c 01 00 00 7c 01 00 00 7c 01 00 00 7c 01 00 00 13 00 00 00 1a 00 00 00 1c 00 00 00 18 00 00 00 15 00 00 00 15 00 00 00 15 00 00 00 15 00 00 00 46 00 00 00 46 00 00 00 96 00 00 00 be 00 00 00 82 00 00 00 82 00 00 00 82 00 00 00 82 00 00 00 20 00 00 00 32 00 00 00 32 00 00 00 32 00 00 00 32 00 00 00 32 00 00 00 2d 00 00 00 2d 00 00 00 08 00 00 00 08 00 00 00 0a 00 00 00 c8 00 00 00 c8 00 00 00 0c 00 00 00 01 00 00 00 01 00 00 00 20 00 00 00 30 00 00 00 34 00 00 00 40 00 00 00 10 00 00 00 10 00 00 00 e8 03 00 00 20 03 00 00 10 00 00 00 10 00 00 00 10 00 00 00 10 00 00 00 10 00 00 00 10 00 00 00 10 00 00 00 10 00 00 00 10 00 00 00 10 00 00 00 10 00 00 00 10 00 00 00 0c 00 00 00 32 00 00 00 32 00 00 00 8c 00 00 00 14 00 00 00 14 00 00 00 0c 00 00 00 12 00 00 00 18 00 00 00 20 00 00 00 00 00 00 00 08 00 00 00 0c 00 00 00 13 00 00 00 1b 00 00 00 24 00 00 00 2b 00 00 00 34 00 00 00 00 00 00 00 08 00 00 00 13 00 00 00 21 00 00 00 2e 00 00 00 39 00 00 00 45 00 00 00 50 00 00 00 20 00 00 00 20 00 00 00 c8 00 00 00 c8 00 00 00 00 00 00 00 90 01 00 00 90 01 00 00 90 01 00 00 bc 02 00 00 bc 02 00 00 04 00 00 00 04 00 00 00 03 00 00 00 04 00 00 00 04 00 00 00 04 00 00 00 04 00 00 00 04 00 00 00 04 00 00 00 05 00 00 00 05 00 00 00 05 00 00 00 06 00 00 00 07 00 00 00 07 00 00 00 08 00 00 00 8c 00 00 00 05 00 00 00 f4 01 00 00 f4 01 00 00 f4 01 00 00 f4 01 00 00 58 02 00 00 84 03 00 00 84 03 00 00 84 03 00 00 0e 00 00 00 0f 00 00 00 0f 00 00 00 0e 00 00 00 0e 00 00 00 0c 00 00 00 0c 00 00 00 0c 00 00 00 fe 01 00 00 fe 01 00 00 fe 01 00 00 fe 01 00 00 fe 01 00 00 12 02 00 00 12 02 00 00 12 02 00 00 3c 00 00 00 3c 00 00 00 3c 00 00 00 3c 00 00 00 3c 00 00 00 32 00 00 00 32 00 00 00 32 00 00 00 08 00 00 00 10 00 00 00 03 00 00 00 b4 00 00 00 e6 00 00 00 03 00 00 00 01 00 00 00 01 00 00 00 20 00 00 00 30 00 00 00 50 00 00 00 64 00 00 00 80 00 00 00 40 00 00 00 dc 05 00 00 dc 05 00 00 10 00 00 00 10 00 00 00 20 00 00 00 20 00 00 00 10 00 00 00 10 00 00 00 10 00 00 00 10 00 00 00 10 00 00 00 10 00 00 00 10 00 00 00 10 00 00 00 10 00 00 00 40 00 00 00 80 00 00 00 40 00 00 00 20 00 00 00 00 00 00 00 08 00 00 00 10 00 00 00 18 00 00 00 1c 00 00 00 00 00 00 00 05 00 00 00 0e 00 00 00 15 00 00 00 20 00 00 00 24 00 00 00 2f 00 00 00 3a 00 00 00 00 00 00 00 03 00 00 00 0b 00 00 00 0e 00 00 00 16 00 00 00 18 00 00 00 20 00 00 00 26 00 00 00 80 00 00 00 40 00 00 00 c8 00 00 00 c8 00 00 00 00 00 00 00 90 01 00 00 90 01 00 00 90 01 00 00 bc 02 00 00 bc 02 00 00 04 00 00 00 04 00 00 00 03 00 00 00 04 00 00 00 04 00 00 00 04 00 00 00 04 00 00 00 04 00 00 00 04 00 00 00 05 00 00 00 05 00 00 00 05 00 00 00 06 00 00 00 07 00 00 00 07 00 00 00 08 00 00 00 8c 00 00 00 05 00 00 00 f4 01 00 00 f4 01 00 00 f4 01 00 00 f4 01 00 00 58 02 00 00 84 03 00 00 84 03 00 00 84 03 00 00 0e 00 00 00 0f 00 00 00 0f 00 00 00 0e 00 00 00 0e 00 00 00 0c 00 00 00 0c 00 00 00 0c 00 00 00 fe 01 00 00 fe 01 00 00 fe 01 00 00 fe 01 00 00 fe 01 00 00 12 02 00 00 12 02 00 00 12 02 00 00 3c 00 00 00 3c 00 00 00 3c 00 00 00 3c 00 00 00 3c 00 00 00 32 00 00 00 32 00 00 00 32 00 00 00 08 00 00 00 10 00 00 00 03 00 00 00 b4 00 00 00 e6 00 00 00 03 00 00 00 01 00 00 00 01 00 00 00 20 00 00 00 30 00 00 00 50 00 00 00 64 00 00 00 80 00 00 00 40 00 00 00 dc 05 00 00 dc 05 00 00 10 00 00 00 10 00 00 00 20 00 00 00 20 00 00 00 10 00 00 00 10 00 00 00 10 00 00 00 10 00 00 00 10 00 00 00 10 00 00 00 10 00 00 00 10 00 00 00 08 00 00 00 40 00 00 00 80 00 00 00 40 00 00 00 20 00 00 00 00 00 00 00 08 00 00 00 10 00 00 00 18 00 00 00 1c 00 00 00 00 00 00 00 02 00 00 00 0e 00 00 00 15 00 00 00 20 00 00 00 24 00 00 00 2f 00 00 00 3a 00 00 00 00 00 00 00 03 00 00 00 0b 00 00 00 0e 00 00 00 16 00 00 00 18 00 00 00 20 00 00 00 26 00 00 00 80 00 00 00 40 00 00 00 c8 00 00 00 c8 00 00 00 00 00 00 00 90 01 00 00 90 01 00 00 90 01 00 00 bc 02 00 00 bc 02 00 00 04 00 00 00 04 00 00 00 03 00 00 00 04 00 00 00 04 00 00 00 04 00 00 00 04 00 00 00 04 00 00 00 04 00 00 00 05 00 00 00 05 00 00 00 05 00 00 00 06 00 00 00 07 00 00 00 07 00 00 00 08 00 00 00 8c 00 00 00 05 00 00 00 f4 01 00 00 f4 01 00 00 f4 01 00 00 f4 01 00 00 58 02 00 00 84 03 00 00 84 03 00 00 84 03 00 00 0e 00 00 00 0f 00 00 00 0f 00 00 00 0e 00 00 00 0e 00 00 00 0c 00 00 00 0c 00 00 00 0c 00 00 00 fe 01 00 00 fe 01 00 00 fe 01 00 00 fe 01 00 00 fe 01 00 00 12 02 00 00 12 02 00 00 12 02 00 00 3c 00 00 00 3c 00 00 00 3c 00 00 00 3c 00 00 00 3c 00 00 00 32 00 00 00 32 00 00 00 32 00 00 00 08 00 00 00 10 00 00 00 03 00 00 00 b4 00 00 00 e6 00 00 00 03 00 00 00 01 00 00 00 01 00 00 00 20 00 00 00 30 00 00 00 50 00 00 00 64 00 00 00 80 00 00 00 40 00 00 00 dc 05 00 00 dc 05 00 00 10 00 00 00 10 00 00 00 20 00 00 00 20 00 00 00 10 00 00 00 10 00 00 00 10 00 00 00 10 00 00 00 10 00 00 00 10 00 00 00 10 00 00 00 10 00 00 00 08 00 00 00 40 00 00 00 80 00 00 00 40 00 00 00 20 00 00 00 00 00 00 00 08 00 00 00 10 00 00 00 18 00 00 00 1c 00 00 00 00 00 00 00 02 00 00 00 0e 00 00 00 15 00 00 00 20 00 00 00 24 00 00 00 2f 00 00 00 3a 00 00 00 00 00 00 00 03 00 00 00 0b 00 00 00 0e 00 00 00 16 00 00 00 18 00 00 00 20 00 00 00 26 00 00 00 80 00 00 00 40 00 00 00 c8 00 00 00 c8 00 00 00 00 00 00 00 90 01 00 00 90 01 00 00 90 01 00 00 bc 02 00 00 bc 02 00 00 04 00 00 00 04 00 00 00 03 00 00 00 04 00 00 00 04 00 00 00 04 00 00 00 04 00 00 00 04 00 00 00 04 00 00 00 05 00 00 00 05 00 00 00 05 00 00 00 06 00 00 00 07 00 00 00 07 00 00 00 08 00 00 00 8c 00 00 00 05 00 00 00 f4 01 00 00 f4 01 00 00 f4 01 00 00 f4 01 00 00 58 02 00 00 84 03 00 00 84 03 00 00 84 03 00 00 0e 00 00 00 0f 00 00 00 0f 00 00 00 0e 00 00 00 0e 00 00 00 0c 00 00 00 0c 00 00 00 0c 00 00 00 fe 01 00 00 fe 01 00 00 fe 01 00 00 fe 01 00 00 fe 01 00 00 12 02 00 00 12 02 00 00 12 02 00 00 3c 00 00 00 3c 00 00 00 3c 00 00 00 3c 00 00 00 3c 00 00 00 32 00 00 00 32 00 00 00 32 00 00 00 08 00 00 00 10 00 00 00 03 00 00 00 b4 00 00 00 e6 00 00 00 03 00 00 00 01 00 00 00 01 00 00 00 20 00 00 00 30 00 00 00 50 00 00 00 64 00 00 00 80 00 00 00 40 00 00 00 dc 05 00 00 dc 05 00 00 10 00 00 00 10 00 00 00 20 00 00 00 20 00 00 00 10 00 00 00 10 00 00 00 10 00 00 00 10 00 00 00 10 00 00 00 10 00 00 00 10 00 00 00 10 00 00 00 00 00 00 00 40 00 00 00 80 00 00 00 40 00 00 00 20 00 00 00 00 00 00 00 08 00 00 00 10 00 00 00 18 00 00 00 1c 00 00 00 00 00 00 00 02 00 00 00 0e 00 00 00 15 00 00 00 20 00 00 00 24 00 00 00 2f 00 00 00 3a 00 00 00 00 00 00 00 03 00 00 00 0b 00 00 00 0e 00 00 00 16 00 00 00 18 00 00 00 20 00 00 00 26 00 00 00 80 00 00 00 40 00 00 00 c8 00 00 00 c8 00 00 00 00 00 00 00 90 01 00 00 90 01 00 00 90 01 00 00 bc 02 00 00 bc 02 00 00 04 00 00 00 04 00 00 00 03 00 00 00 04 00 00 00 04 00 00 00 04 00 00 00 04 00 00 00 04 00 00 00 04 00 00 00 05 00 00 00 05 00 00 00 05 00 00 00 06 00 00 00 07 00 00 00 07 00 00 00 08 00 00 00 8c 00 00 00 05 00 00 00 f4 01 00 00 f4 01 00 00 f4 01 00 00 f4 01 00 00 58 02 00 00 84 03 00 00 84 03 00 00 84 03 00 00 0e 00 00 00 0f 00 00 00 0f 00 00 00 0e 00 00 00 0e 00 00 00 0c 00 00 00 0c 00 00 00 0c 00 00 00 fe 01 00 00 fe 01 00 00 fe 01 00 00 fe 01 00 00 fe 01 00 00 12 02 00 00 12 02 00 00 12 02 00 00 3c 00 00 00 3c 00 00 00 3c 00 00 00 3c 00 00 00 3c 00 00 00 32 00 00 00 32 00 00 00 32 00 00 00 08 00 00 00 10 00 00 00 03 00 00 00 b4 00 00 00 e6 00 00 00 03 00 00 00 01 00 00 00 01 00 00 00 20 00 00 00 30 00 00 00 50 00 00 00 64 00 00 00 80 00 00 00 40 00 00 00 dc 05 00 00 dc 05 00 00 10 00 00 00 10 00 00 00 20 00 00 00 20 00 00 00 10 00 00 00 10 00 00 00 10 00 00 00 10 00 00 00 10 00 00 00 10 00 00 00 10 00 00 00 10 00 00 00 00 00 00 00 40 00 00 00 80 00 00 00 40 00 00 00 20 00 00 00 00 00 00 00 08 00 00 00 10 00 00 00 18 00 00 00 1c 00 00 00 00 00 00 00 02 00 00 00 0e 00 00 00 15 00 00 00 20 00 00 00 24 00 00 00 2f 00 00 00 3a 00 00 00 00 00 00 00 03 00 00 00 0b 00 00 00 0e 00 00 00 16 00 00 00 18 00 00 00 20 00 00 00 26 00 00 00 80 00 00 00 40 00 00 00 c8 00 00 00 c8 00 00 00 00 00 00 00 90 01 00 00 90 01 00 00 90 01 00 00 bc 02 00 00 bc 02 00 00 04 00 00 00 04 00 00 00 03 00 00 00 04 00 00 00 04 00 00 00 04 00 00 00 04 00 00 00 04 00 00 00 04 00 00 00 05 00 00 00 05 00 00 00 05 00 00 00 06 00 00 00 07 00 00 00 07 00 00 00 08 00 00 00 8c 00 00 00 05 00 00 00 f4 01 00 00 f4 01 00 00 f4 01 00 00 f4 01 00 00 58 02 00 00 84 03 00 00 84 03 00 00 84 03 00 00 0e 00 00 00 0f 00 00 00 0f 00 00 00 0e 00 00 00 0e 00 00 00 0c 00 00 00 0c 00 00 00 0c 00 00 00 fe 01 00 00 fe 01 00 00 fe 01 00 00 fe 01 00 00 fe 01 00 00 12 02 00 00 12 02 00 00 12 02 00 00 3c 00 00 00 3c 00 00 00 3c 00 00 00 3c 00 00 00 3c 00 00 00 32 00 00 00 32 00 00 00 32 00 00 00 08 00 00 00 10 00 00 00 03 00 00 00 b4 00 00 00 e6 00 00 00 03 00 00 00 01 00 00 00 01 00 00 00 20 00 00 00 30 00 00 00 50 00 00 00 64 00 00 00 80 00 00 00 40 00 00 00 dc 05 00 00 dc 05 00 00 10 00 00 00 10 00 00 00 20 00 00 00 20 00 00 00 10 00 00 00 10 00 00 00 10 00 00 00 10 00 00 00 10 00 00 00 10 00 00 00 10 00 00 00 10 00 00 00 00 00 00 00 40 00 00 00 80 00 00 00 40 00 00 00 20 00 00 00 00 00 00 00 08 00 00 00 10 00 00 00 18 00 00 00 1c 00 00 00 00 00 00 00 02 00 00 00 0e 00 00 00 15 00 00 00 20 00 00 00 24 00 00 00 2f 00 00 00 3a 00 00 00 00 00 00 00 03 00 00 00 0b 00 00 00 0e 00 00 00 16 00 00 00 18 00 00 00 20 00 00 00 26 00 00 00 80 00 00 00 40 00 00 00 c8 00 00 00 c8 00 00 00 00 00 00 00 90 01 00 00 90 01 00 00 90 01 00 00 bc 02 00 00 bc 02 00 00 04 00 00 00 04 00 00 00 03 00 00 00 04 00 00 00 04 00 00 00 04 00 00 00 04 00 00 00 04 00 00 00 04 00 00 00 05 00 00 00 05 00 00 00 05 00 00 00 06 00 00 00 07 00 00 00 07 00 00 00 08 00 00 00 8c 00 00 00 05 00 00 00 f4 01 00 00 f4 01 00 00 f4 01 00 00 f4 01 00 00 58 02 00 00 84 03 00 00 84 03 00 00 84 03 00 00 0e 00 00 00 0f 00 00 00 0f 00 00 00 0e 00 00 00 0e 00 00 00 0c 00 00 00 0c 00 00 00 0c 00 00 00 fe 01 00 00 fe 01 00 00 fe 01 00 00 fe 01 00 00 fe 01 00 00 12 02 00 00 12 02 00 00 12 02 00 00 3c 00 00 00 3c 00 00 00 3c 00 00 00 3c 00 00 00 3c 00 00 00 32 00 00 00 32 00 00 00 32 00 00 00 08 00 00 00 10 00 00 00 03 00 00 00 b4 00 00 00 e6 00 00 00 03 00 00 00 01 00 00 00 01 00 00 00 20 00 00 00 30 00 00 00 50 00 00 00 64 00 00 00 80 00 00 00 40 00 00 00 dc 05 00 00 dc 05 00 00 10 00 00 00 10 00 00 00 20 00 00 00 20 00 00 00 10 00 00 00 10 00 00 00 10 00 00 00 10 00 00 00 10 00 00 00 10 00 00 00 10 00 00 00 10 00 00 00 00 00 00 00 40 00 00 00 80 00 00 00 40 00 00 00 20 00 00 00 00 00 00 00 08 00 00 00 10 00 00 00 18 00 00 00 1c 00 00 00 00 00 00 00 02 00 00 00 0e 00 00 00 15 00 00 00 20 00 00 00 24 00 00 00 2f 00 00 00 3a 00 00 00 00 00 00 00 03 00 00 00 0b 00 00 00 0e 00 00 00 16 00 00 00 18 00 00 00 20 00 00 00 26 00 00 00 80 00 00 00 40 00 00 00 c8 00 00 00 c8 00 00 00 00 00 00 00 90 01 00 00 90 01 00 00 90 01 00 00 bc 02 00 00 bc 02 00 00 04 00 00 00 04 00 00 00 03 00 00 00 04 00 00 00 04 00 00 00 04 00 00 00 04 00 00 00 04 00 00 00 04 00 00 00 05 00 00 00 05 00 00 00 05 00 00 00 06 00 00 00 07 00 00 00 07 00 00 00 08 00 00 00 8c 00 00 00 05 00 00 00 f4 01 00 00 f4 01 00 00 f4 01 00 00 f4 01 00 00 58 02 00 00 84 03 00 00 84 03 00 00 84 03 00 00 0e 00 00 00 0f 00 00 00 0f 00 00 00 0e 00 00 00 0e 00 00 00 0c 00 00 00 0c 00 00 00 0c 00 00 00 fe 01 00 00 fe 01 00 00 fe 01 00 00 fe 01 00 00 fe 01 00 00 12 02 00 00 12 02 00 00 12 02 00 00 3c 00 00 00 3c 00 00 00 3c 00 00 00 3c 00 00 00 3c 00 00 00 32 00 00 00 32 00 00 00 32 00 00 00 08 00 00 00 10 00 00 00 03 00 00 00 b4 00 00 00 e6 00 00 00 03 00 00 00 01 00 00 00 01 00 00 00 20 00 00 00 30 00 00 00 50 00 00 00 64 00 00 00 80 00 00 00 40 00 00 00 dc 05 00 00 dc 05 00 00 10 00 00 00 10 00 00 00 20 00 00 00 20 00 00 00 10 00 00 00 10 00 00 00 10 00 00 00 10 00 00 00 10 00 00 00 10 00 00 00 10 00 00 00 10 00 00 00 00 00 00 00 40 00 00 00 80 00 00 00 40 00 00 00 20 00 00 00 00 00 00 00 08 00 00 00 10 00 00 00 18 00 00 00 1c 00 00 00 00 00 00 00 02 00 00 00 0e 00 00 00 15 00 00 00 20 00 00 00 24 00 00 00 2f 00 00 00 3a 00 00 00 00 00 00 00 03 00 00 00 0b 00 00 00 0e 00 00 00 16 00 00 00 18 00 00 00 20 00 00 00 26 00 00 00 80 00 00 00 40 00 00 00];
		};
		iq_pfr {
			size = [d8 00 00 00];
			data = [00 00 00 00 00 00 00 00 00 00 00 00 00 00 00 00 00 00 00 00 08 00 00 00 70 00 00 00 e8 00 00 00 ff 00 00 00 ff 00 00 00 ff 00 00 00 ff 00 00 00 ff 00 00 00 ff 00 00 00 ff 00 00 00 af 00 00 00 91 00 00 00 01 00 00 00 91 00 00 00 af 00 00 00 e0 00 00 00 2c 01 00 00 e0 00 00 00 2c 01 00 00 e0 00 00 00 2c 01 00 00 e0 00 00 00 2c 01 00 00 e0 00 00 00 2c 01 00 00 e0 00 00 00 2c 01 00 00 e0 00 00 00 2c 01 00 00 e0 00 00 00 2c 01 00 00 e0 00 00 00 2c 01 00 00 e0 00 00 00 2c 01 00 00 e0 00 00 00 2c 01 00 00 e0 00 00 00 2c 01 00 00 e0 00 00 00 2c 01 00 00 e0 00 00 00 2c 01 00 00 e0 00 00 00 2c 01 00 00 e0 00 00 00 2c 01 00 00 e0 00 00 00 2c 01 00 00];
		};
		iq_wdr {
			size = [e4 02 00 00];
			data = [00 00 00 00 00 00 00 00 20 00 00 00 12 00 00 00 80 00 00 00 05 00 00 00 03 00 00 00 00 00 00 00 01 00 00 00 02 00 00 00 06 00 00 00 0e 00 00 00 16 00 00 00 1e 00 00 00 22 00 00 00 26 00 00 00 28 00 00 00 2a 00 00 00 2b 00 00 00 2c 00 00 00 2d 00 00 00 2e 00 00 00 2f 00 00 00 30 00 00 00 31 00 00 00 32 00 00 00 33 00 00 00 34 00 00 00 35 00 00 00 36 00 00 00 37 00 00 00 38 00 00 00 39 00 00 00 3a 00 00 00 3b 00 00 00 3c 00 00 00 3d 00 00 00 3e 00 00 00 3f 00 00 00 00 00 00 00 00 00 00 00 02 00 00 00 03 00 00 00 03 00 00 00 03 00 00 00 02 00 00 00 02 00 00 00 01 00 00 00 01 00 00 00 00 00 00 00 00 00 00 00 00 00 00 00 00 00 00 00 00 00 00 00 00 00 00 00 00 00 00 00 00 00 00 00 00 00 00 00 00 00 00 00 00 00 00 00 00 00 00 00 00 00 00 00 00 00 00 00 00 00 00 00 00 00 00 00 00 00 00 00 00 00 00 00 00 00 00 00 00 00 00 00 00 00 00 00 00 00 00 00 ff 0f 00 00 f8 0f 00 00 ab 0f 00 00 82 0f 00 00 4e 0f 00 00 0d 0f 00 00 c0 0e 00 00 94 0e 00 00 66 0e 00 00 35 0e 00 00 00 0e 00 00 ca 0d 00 00 90 0d 00 00 55 0d 00 00 17 0d 00 00 d8 0c 00 00 97 0c 00 00 55 0c 00 00 12 0c 00 00 cf 0b 00 00 8b 0b 00 00 47 0b 00 00 03 0b 00 00 c0 0a 00 00 7d 0a 00 00 3b 0a 00 00 fa 09 00 00 ba 09 00 00 7b 09 00 00 3e 09 00 00 03 09 00 00 91 08 00 00 25 08 00 00 c1 07 00 00 64 07 00 00 0e 07 00 00 be 06 00 00 76 06 00 00 33 06 00 00 be 05 00 00 5c 05 00 00 0b 05 00 00 c8 04 00 00 60 04 00 00 17 04 00 00 e2 03 00 00 bc 03 00 00 a0 03 00 00 8b 03 00 00 7a 03 00 00 6e 03 00 00 64 03 00 00 5c 03 00 00 55 03 00 00 50 03 00 00 4c 03 00 00 49 03 00 00 46 03 00 00 43 03 00 00 41 03 00 00 40 03 00 00 3e 03 00 00 3d 03 00 00 3c 03 00 00 3b 03 00 00 20 00 00 00 40 00 00 00 40 00 00 00 44 00 00 00 40 00 00 00 30 00 00 00 34 00 00 00 40 00 00 00 20 00 00 00 22 00 00 00 40 00 00 00 10 00 00 00 14 00 00 00 40 00 00 00 08 00 00 00 0c 00 00 00 40 00 00 00 00 00 00 00 ff 00 00 00 40 00 00 00 00 00 00 00 ff 00 00 00 40 00 00 00 00 00 00 00 ff 00 00 00 40 00 00 00 00 00 00 00 ff 00 00 00 40 00 00 00 00 00 00 00 ff 00 00 00 40 00 00 00 00 00 00 00 ff 00 00 00 40 00 00 00 00 00 00 00 ff 00 00 00 40 00 00 00 00 00 00 00 ff 00 00 00 40 00 00 00 00 00 00 00 ff 00 00 00 40 00 00 00 00 00 00 00 ff 00 00 00 40 00 00 00 00 00 00 00 ff 00 00 00];
		};
		iq_defog {
			size = [84 00 00 00];
			data = [00 00 00 00 01 00 00 00 01 00 00 00 07 00 00 03 ff 60 c0 c0 c0 c0 c0 c0 c0 c0 c0 c0 c0 c0 c0 c0 c0 c0 c0 00 28 00 00 03 ff 80 28 00 00 03 ff 80 28 00 00 03 ff 80 28 00 00 03 ff 80 28 00 00 03 ff 80 28 00 00 03 ff 80 28 00 00 03 ff 80 28 00 00 03 ff 80 28 00 00 03 ff 80 28 00 00 03 ff 80 28 00 00 03 ff 80 28 00 00 03 ff 80 28 00 00 03 ff 80 28 00 00 03 ff 80 28 00 00 03 ff 80 28 00 00 03 ff 80];
		};
		iq_shdr {
			size = [f0 01 00 00];
			data = [00 00 00 00 00 00 00 00 10 00 00 00 01 00 00 00 00 0c 09 00 c0 00 06 00 02 00 00 00 00 0c 09 00 c0 00 06 00 00 01 00 02 04 08 0a 0c 0e 10 0e 0c 0a 08 06 04 02 00 00 00 00 00 00 00 08 00 02 04 06 08 0a 0c 0e 10 12 14 16 18 1a 1c 1e 20 22 24 26 28 2a 2c 2e 30 32 34 36 38 3a 3c 3e 01 01 01 01 01 01 01 01 01 01 01 01 01 01 01 01 01 01 01 01 01 01 01 01 01 01 01 01 01 01 01 01 00 00 00 43 03 e9 04 06 06 de 06 8b 07 1c 08 98 08 05 09 67 09 be 09 0e 0a 57 0a 9b 0a d9 0a 14 0b 4b 0b 7f 0b b0 0b de 0b 0a 0c 34 0c 5c 0c 83 0c a8 0c cb 0c ed 0c 0d 0d 2d 0d 4b 0d 69 0d 85 0d a1 0d bc 0d d6 0d ef 0d 08 0e 20 0e 37 0e 4e 0e 64 0e 79 0e 8e 0e a3 0e b7 0e cb 0e de 0e f1 0e 03 0f 15 0f 27 0f 38 0f 49 0f 5a 0f 6a 0f 7a 0f 8a 0f 9a 0f a9 0f b8 0f c7 0f d5 0f e4 0f f2 0f ff 0f 00 01 04 05 06 07 08 08 00 00 01 02 03 00 e0 00 04 05 06 07 08 08 00 00 01 02 03 00 e0 00 04 05 06 07 08 08 00 00 01 02 03 00 e0 00 04 05 06 07 08 08 00 00 01 02 03 00 e0 00 04 05 06 07 08 08 00 00 01 02 03 00 e0 00 04 05 06 07 08 08 00 00 01 02 03 00 e0 00 04 05 06 07 08 08 00 00 01 02 03 00 e0 00 04 05 06 07 08 08 00 00 01 02 03 00 e0 00 04 05 06 07 08 08 00 00 01 02 03 00 e0 00 04 05 06 07 08 08 00 00 01 02 03 00 e0 00 04 05 06 07 08 08 00 00 01 02 03 00 e0 00 04 05 06 07 08 08 00 00 01 02 03 00 e0 00 04 05 06 07 08 08 00 00 01 02 03 00 e0 00 04 05 06 07 08 08 00 00 01 02 03 00 e0 00 04 05 06 07 08 08 00 00 01 02 03 00 e0 00 04 05 06 07 08 08 00 00 01 02 03 00 e0 00 04 05 06 07 08 08 00 00 01 02 03 00 00 00];
		};
		iq_rgbir {
			size = [28 00 00 00];
			data = [00 00 00 00 cc 00 00 00 cc 00 00 00 e6 00 00 00 00 01 00 00 cc 00 00 00 cc 00 00 00 e6 00 00 00 dc 00 00 00 f0 00 00 00];
		};
		iq_companding {
			size = [18 01 00 00];
			data = [00 02 00 00 00 03 00 00 00 0a 00 00 ff 0f 00 00 ff 0f 00 00 ff 0f 00 00 ff 0f 00 00 ff 0f 00 00 ff 0f 00 00 ff 0f 00 00 ff 0f 00 00 00 00 00 00 00 01 00 00 00 02 00 00 00 08 00 00 00 08 00 00 00 08 00 00 00 08 00 00 00 08 00 00 00 08 00 00 00 08 00 00 00 08 00 00 00 08 00 00 04 00 00 00 05 00 00 00 06 00 00 00 08 00 00 00 08 00 00 00 08 00 00 00 08 00 00 00 08 00 00 00 08 00 00 00 08 00 00 00 08 00 00 00 08 00 00 00 0a 00 00 00 0b 00 00 00 0c 00 00 00 0d 00 00 00 0e 00 00 00 0f 00 00 00 10 00 00 00 10 00 00 00 10 00 00 00 10 00 00 00 10 00 00 00 00 00 00 00 00 02 00 00 00 04 00 00 00 06 00 00 00 08 00 00 00 0a 00 00 00 0c 00 00 00 0c 00 00 00 0c 00 00 00 0c 00 00 00 0c 00 00 00 0c 00 00 03 00 00 00 04 00 00 00 05 00 00 00 06 00 00 00 07 00 00 00 08 00 00 00 09 00 00 00 09 00 00 00 09 00 00 00 09 00 00 00 09 00 00 00 09 00 00 00];
		};
		iq_post_3dnr {
			size = [40 02 00 00];
			data = [01 00 00 00 00 00 00 00 01 00 00 00 06 08 0a 10 08 00 10 10 10 01 02 01 01 02 01 0a 0f 14 0a 0f 14 01 03 01 01 03 01 0a 0f 14 0a 0f 14 02 03 04 10 08 00 04 04 04 01 02 01 01 02 01 0a 0f 14 0a 0f 14 01 03 01 01 03 01 0a 0f 14 0a 0f 14 02 03 04 10 08 00 04 04 04 01 02 01 01 02 01 0f 14 19 0f 14 19 01 03 01 01 03 01 0f 14 19 0f 14 19 03 04 05 10 08 00 05 04 04 01 02 01 01 02 01 14 1e 28 14 1e 28 01 03 01 01 03 01 14 1e 28 14 1e 28 04 05 06 10 08 00 06 08 08 01 03 01 01 03 01 1e 28 32 1e 28 32 01 03 01 01 03 01 1e 28 32 1e 28 32 05 06 07 10 08 00 07 08 08 01 03 01 01 03 01 28 32 3c 28 32 3c 01 03 01 01 03 01 28 32 3c 28 32 3c 06 07 08 10 08 00 08 10 10 01 03 01 01 03 01 32 3c 46 32 3c 46 01 03 01 01 03 01 32 3c 46 32 3c 46 07 08 09 10 08 00 09 10 10 01 03 01 01 03 01 3c 46 50 3c 46 50 01 03 01 01 03 01 3c 46 50 3c 46 50 08 09 0a 10 08 00 0a 10 10 01 03 01 01 03 01 46 50 5a 46 50 5a 01 03 01 01 03 01 46 50 5a 46 50 5a 09 0a 0b 10 08 00 0b 10 10 01 03 01 01 03 01 50 5a 64 50 5a 64 01 03 01 01 03 01 50 5a 64 50 5a 64 0a 0b 0c 10 08 00 0c 10 10 01 03 01 01 03 01 5a 64 6e 5a 64 6e 01 03 01 01 03 01 5a 64 6e 5a 64 6e 0b 0c 0d 10 08 00 0d 10 10 01 03 01 01 03 01 64 78 8c 64 78 8c 01 03 01 01 03 01 64 78 8c 64 78 8c 0c 0d 0e 10 08 00 0d 10 10 01 03 01 01 03 01 64 78 8c 64 78 8c 01 03 01 01 03 01 64 78 8c 64 78 8c 0d 0e 0f 10 08 00 0d 10 10 01 03 01 01 03 01 64 78 8c 64 78 8c 01 03 01 01 03 01 64 78 8c 64 78 8c 0e 0f 10 10 08 00 0d 10 10 01 03 01 01 03 01 64 78 8c 64 78 8c 01 03 01 01 03 01 64 78 8c 64 78 8c 0f 10 11 10 08 00 0d 10 10 01 03 01 01 03 01 64 78 8c 64 78 8c 01 03 01 01 03 01 64 78 8c 64 78 8c 0f 10 11 10 08 00 0d 10 10 01 03 01 01 03 01 64 78 8c 64 78 8c 01 03 01 01 03 01 64 78 8c 64 78 8c 00 00 00];
		};
		iq_rgbir_enh {
			size = [18 01 00 00];
			data = [01 00 00 00 00 00 00 00 32 00 00 00 10 00 00 00 10 00 00 00 10 00 00 00 10 00 00 00 10 00 00 00 10 00 00 00 10 00 00 00 10 00 00 00 10 00 00 00 10 00 00 00 10 00 00 00 10 00 00 00 10 00 00 00 10 00 00 00 10 00 00 00 10 00 00 00 80 00 00 00 20 00 00 00 20 00 00 00 20 00 00 00 20 00 00 00 20 00 00 00 20 00 00 00 20 00 00 00 20 00 00 00 20 00 00 00 20 00 00 00 20 00 00 00 20 00 00 00 20 00 00 00 20 00 00 00 20 00 00 00 20 00 00 00 98 00 00 00 50 00 00 00 50 00 00 00 50 00 00 00 50 00 00 00 50 00 00 00 50 00 00 00 50 00 00 00 50 00 00 00 50 00 00 00 50 00 00 00 50 00 00 00 50 00 00 00 50 00 00 00 50 00 00 00 50 00 00 00 50 00 00 00 ff 00 00 00 a0 00 00 00 a0 00 00 00 a0 00 00 00 a0 00 00 00 a0 00 00 00 a0 00 00 00 a0 00 00 00 a0 00 00 00 a0 00 00 00 a0 00 00 00 a0 00 00 00 a0 00 00 00 a0 00 00 00 a0 00 00 00 a0 00 00 00 a0 00 00 00];
		};
	};
};
